VERSION ""

NS_ :

BS_:

BU_: ORIN RPI TOOL DRIVE1 DRIVE2 DRIVE3 DRIVE4 DRIVE5 DRIVE6 FPGA ANY

BO_ 0 ESTOP: 1 ANY
  SG_ MAGIC : 0|8@1+ (1,0) [0|255] "" ORIN,RPI,TOOL,DRIVE1,DRIVE2,DRIVE3,DRIVE4,DRIVE5,DRIVE6,FPGA

BO_ 1 ESTOP_RELEASE: 2 ORIN
  SG_ MASTER_NODE_ID : 0|8@1+ (1,0) [0|31] "" ORIN,RPI,TOOL,DRIVE1,DRIVE2,DRIVE3,DRIVE4,DRIVE5,DRIVE6,FPGA
  SG_ MASTER_TERM : 8|8@1+ (1,0) [0|255] "" ORIN,RPI,TOOL,DRIVE1,DRIVE2,DRIVE3,DRIVE4,DRIVE5,DRIVE6,FPGA

BO_ 2 SYNC: 1 ORIN
  SG_ CYCLE_COUNTER : 0|8@1+ (1,0) [0|255] "" ORIN,RPI,TOOL,DRIVE1,DRIVE2,DRIVE3,DRIVE4,DRIVE5,DRIVE6,FPGA

BO_ 3 NMT: 4 ORIN
  SG_ TARGET_NODE : 0|8@1+ (1,0) [0|31] "" ORIN,RPI,TOOL,DRIVE1,DRIVE2,DRIVE3,DRIVE4,DRIVE5,DRIVE6,FPGA
  SG_ COMMAND : 8|8@1+ (1,0) [0|5] "" ORIN,RPI,TOOL,DRIVE1,DRIVE2,DRIVE3,DRIVE4,DRIVE5,DRIVE6,FPGA
  SG_ MASTER_NODE_ID : 16|8@1+ (1,0) [0|31] "" ORIN,RPI,TOOL,DRIVE1,DRIVE2,DRIVE3,DRIVE4,DRIVE5,DRIVE6,FPGA
  SG_ MASTER_TERM : 24|8@1+ (1,0) [0|255] "" ORIN,RPI,TOOL,DRIVE1,DRIVE2,DRIVE3,DRIVE4,DRIVE5,DRIVE6,FPGA

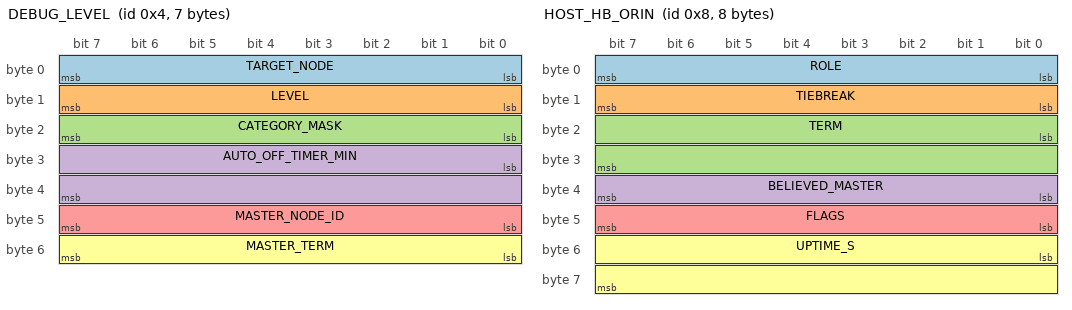
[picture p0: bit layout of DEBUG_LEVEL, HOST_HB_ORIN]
BO_ 4 DEBUG_LEVEL: 7 ORIN
  SG_ TARGET_NODE : 0|8@1+ (1,0) [0|31] "" ORIN,RPI,TOOL,DRIVE1,DRIVE2,DRIVE3,DRIVE4,DRIVE5,DRIVE6,FPGA
  SG_ LEVEL : 8|8@1+ (1,0) [0|3] "" ORIN,RPI,TOOL,DRIVE1,DRIVE2,DRIVE3,DRIVE4,DRIVE5,DRIVE6,FPGA
  SG_ CATEGORY_MASK : 16|8@1+ (1,0) [0|255] "" ORIN,RPI,TOOL,DRIVE1,DRIVE2,DRIVE3,DRIVE4,DRIVE5,DRIVE6,FPGA
  SG_ AUTO_OFF_TIMER_MIN : 24|16@1+ (1,0) [0|65535] "min" ORIN,RPI,TOOL,DRIVE1,DRIVE2,DRIVE3,DRIVE4,DRIVE5,DRIVE6,FPGA
  SG_ MASTER_NODE_ID : 40|8@1+ (1,0) [0|31] "" ORIN,RPI,TOOL,DRIVE1,DRIVE2,DRIVE3,DRIVE4,DRIVE5,DRIVE6,FPGA
  SG_ MASTER_TERM : 48|8@1+ (1,0) [0|255] "" ORIN,RPI,TOOL,DRIVE1,DRIVE2,DRIVE3,DRIVE4,DRIVE5,DRIVE6,FPGA

BO_ 8 HOST_HB_ORIN: 8 ORIN
  SG_ ROLE : 0|8@1+ (1,0) [0|3] "" ORIN,RPI,TOOL
  SG_ TIEBREAK : 8|8@1+ (1,0) [0|255] "" ORIN,RPI,TOOL
  SG_ TERM : 16|16@1+ (1,0) [0|65535] "" ORIN,RPI,TOOL
  SG_ BELIEVED_MASTER : 32|8@1+ (1,0) [0|31] "" ORIN,RPI,TOOL
  SG_ FLAGS : 40|8@1+ (1,0) [0|255] "" ORIN,RPI,TOOL
  SG_ UPTIME_S : 48|16@1+ (1,0) [0|65535] "s" ORIN,RPI,TOOL

BO_ 9 LEAD_REQUEST_ORIN: 2 ORIN
  SG_ REQUESTED_LEADER : 0|8@1+ (1,0) [0|31] "" ORIN,RPI,TOOL
  SG_ REQUEST_COUNTER : 8|8@1+ (1,0) [0|255] "" ORIN,RPI,TOOL

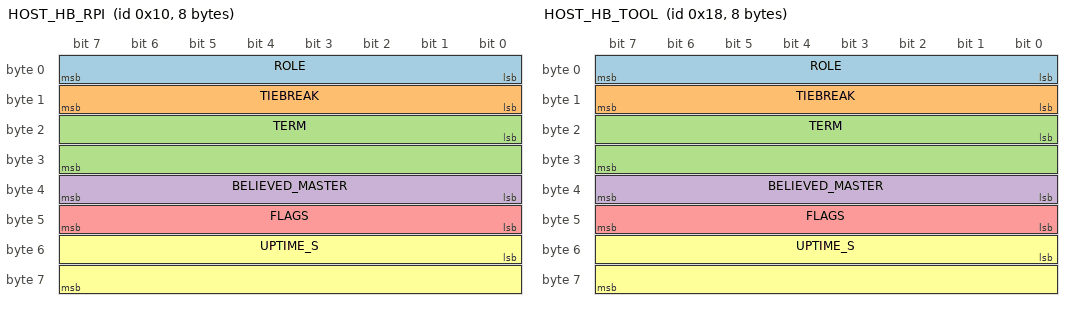
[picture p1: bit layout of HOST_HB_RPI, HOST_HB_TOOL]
BO_ 16 HOST_HB_RPI: 8 RPI
  SG_ ROLE : 0|8@1+ (1,0) [0|3] "" ORIN,RPI,TOOL
  SG_ TIEBREAK : 8|8@1+ (1,0) [0|255] "" ORIN,RPI,TOOL
  SG_ TERM : 16|16@1+ (1,0) [0|65535] "" ORIN,RPI,TOOL
  SG_ BELIEVED_MASTER : 32|8@1+ (1,0) [0|31] "" ORIN,RPI,TOOL
  SG_ FLAGS : 40|8@1+ (1,0) [0|255] "" ORIN,RPI,TOOL
  SG_ UPTIME_S : 48|16@1+ (1,0) [0|65535] "s" ORIN,RPI,TOOL

BO_ 17 LEAD_REQUEST_RPI: 2 RPI
  SG_ REQUESTED_LEADER : 0|8@1+ (1,0) [0|31] "" ORIN,RPI,TOOL
  SG_ REQUEST_COUNTER : 8|8@1+ (1,0) [0|255] "" ORIN,RPI,TOOL

BO_ 24 HOST_HB_TOOL: 8 TOOL
  SG_ ROLE : 0|8@1+ (1,0) [0|3] "" ORIN,RPI,TOOL
  SG_ TIEBREAK : 8|8@1+ (1,0) [0|255] "" ORIN,RPI,TOOL
  SG_ TERM : 16|16@1+ (1,0) [0|65535] "" ORIN,RPI,TOOL
  SG_ BELIEVED_MASTER : 32|8@1+ (1,0) [0|31] "" ORIN,RPI,TOOL
  SG_ FLAGS : 40|8@1+ (1,0) [0|255] "" ORIN,RPI,TOOL
  SG_ UPTIME_S : 48|16@1+ (1,0) [0|65535] "s" ORIN,RPI,TOOL

BO_ 25 LEAD_REQUEST_TOOL: 2 TOOL
  SG_ REQUESTED_LEADER : 0|8@1+ (1,0) [0|31] "" ORIN,RPI,TOOL
  SG_ REQUEST_COUNTER : 8|8@1+ (1,0) [0|255] "" ORIN,RPI,TOOL

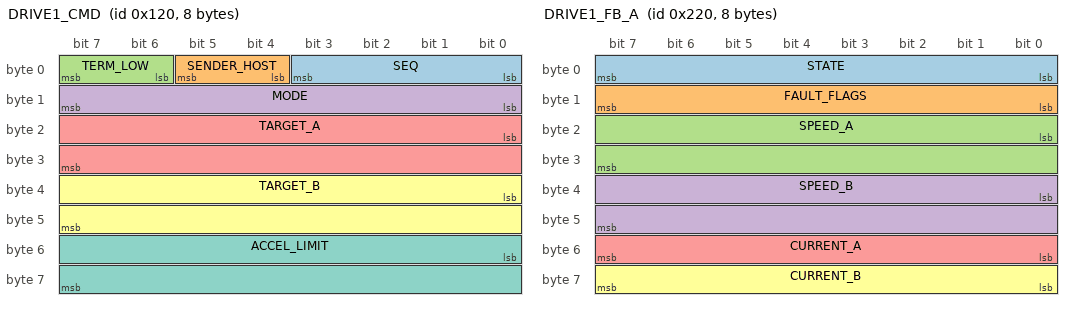
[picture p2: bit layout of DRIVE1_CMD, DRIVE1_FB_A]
BO_ 288 DRIVE1_CMD: 8 ORIN
  SG_ SEQ : 0|4@1+ (1,0) [0|15] "" DRIVE1
  SG_ SENDER_HOST : 4|2@1+ (1,0) [0|3] "" DRIVE1
  SG_ TERM_LOW : 6|2@1+ (1,0) [0|3] "" DRIVE1
  SG_ MODE : 8|8@1+ (1,0) [0|3] "" DRIVE1
  SG_ TARGET_A : 16|16@1- (0.01,0) [-327.68|327.67] "rad/s" DRIVE1
  SG_ TARGET_B : 32|16@1- (0.01,0) [-327.68|327.67] "rad/s" DRIVE1
  SG_ ACCEL_LIMIT : 48|16@1+ (0.01,0) [0|655.35] "rad/s^2" DRIVE1

BO_ 544 DRIVE1_FB_A: 8 DRIVE1
  SG_ STATE : 0|8@1+ (1,0) [0|5] "" ORIN,RPI,TOOL
  SG_ FAULT_FLAGS : 8|8@1+ (1,0) [0|255] "" ORIN,RPI,TOOL
  SG_ SPEED_A : 16|16@1- (0.01,0) [-327.68|327.67] "rad/s" ORIN,RPI,TOOL
  SG_ SPEED_B : 32|16@1- (0.01,0) [-327.68|327.67] "rad/s" ORIN,RPI,TOOL
  SG_ CURRENT_A : 48|8@1+ (0.2,0) [0|51] "A" ORIN,RPI,TOOL
  SG_ CURRENT_B : 56|8@1+ (0.2,0) [0|51] "A" ORIN,RPI,TOOL

BO_ 545 DRIVE1_FB_B: 8 DRIVE1
  SG_ ENCODER_A : 0|32@1- (1,0) [-2147483648|2147483647] "counts" ORIN,RPI,TOOL
  SG_ ENCODER_B : 32|32@1- (1,0) [-2147483648|2147483647] "counts" ORIN,RPI,TOOL

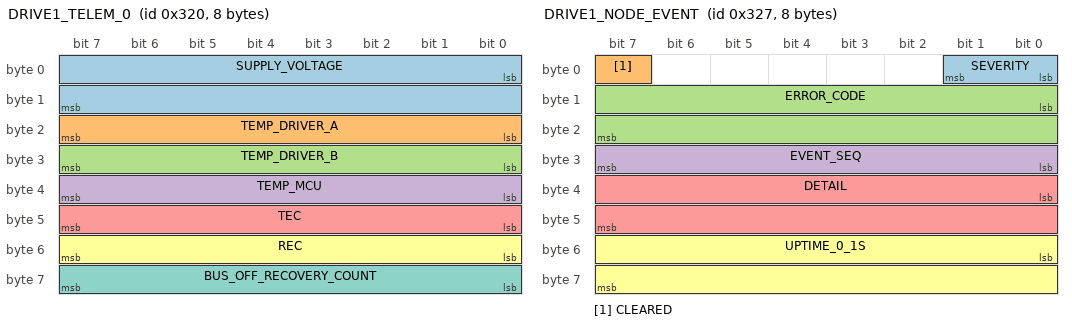
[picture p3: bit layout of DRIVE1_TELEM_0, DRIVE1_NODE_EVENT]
BO_ 800 DRIVE1_TELEM_0: 8 DRIVE1
  SG_ SUPPLY_VOLTAGE : 0|16@1+ (1,0) [0|65535] "mV" ORIN,RPI,TOOL
  SG_ TEMP_DRIVER_A : 16|8@1- (1,0) [-128|127] "degC" ORIN,RPI,TOOL
  SG_ TEMP_DRIVER_B : 24|8@1- (1,0) [-128|127] "degC" ORIN,RPI,TOOL
  SG_ TEMP_MCU : 32|8@1- (1,0) [-128|127] "degC" ORIN,RPI,TOOL
  SG_ TEC : 40|8@1+ (1,0) [0|255] "" ORIN,RPI,TOOL
  SG_ REC : 48|8@1+ (1,0) [0|255] "" ORIN,RPI,TOOL
  SG_ BUS_OFF_RECOVERY_COUNT : 56|8@1+ (1,0) [0|255] "" ORIN,RPI,TOOL

BO_ 801 DRIVE1_TELEM_1: 8 DRIVE1
  SG_ DUTY_A : 0|16@1- (0.01,0) [-327.68|327.67] "%" ORIN,RPI,TOOL
  SG_ DUTY_B : 16|16@1- (0.01,0) [-327.68|327.67] "%" ORIN,RPI,TOOL
  SG_ WATCHDOG_RESET_COUNT : 32|8@1+ (1,0) [0|255] "" ORIN,RPI,TOOL
  SG_ LAST_RESET_CAUSE : 40|8@1+ (1,0) [0|4] "" ORIN,RPI,TOOL
  SG_ COMMANDS_MISSED : 48|16@1+ (1,0) [0|65535] "" ORIN,RPI,TOOL

BO_ 802 DRIVE1_DEBUG_A: 8 DRIVE1
  SG_ SETPOINT : 0|16@1- (0.01,0) [-327.68|327.67] "" ORIN,RPI,TOOL
  SG_ MEASURED : 16|16@1- (0.01,0) [-327.68|327.67] "" ORIN,RPI,TOOL
  SG_ INTEGRATOR : 32|16@1- (0.01,0) [-327.68|327.67] "" ORIN,RPI,TOOL
  SG_ OUTPUT : 48|16@1- (0.01,0) [-327.68|327.67] "" ORIN,RPI,TOOL

BO_ 803 DRIVE1_DEBUG_B: 8 DRIVE1
  SG_ SETPOINT : 0|16@1- (0.01,0) [-327.68|327.67] "" ORIN,RPI,TOOL
  SG_ MEASURED : 16|16@1- (0.01,0) [-327.68|327.67] "" ORIN,RPI,TOOL
  SG_ INTEGRATOR : 32|16@1- (0.01,0) [-327.68|327.67] "" ORIN,RPI,TOOL
  SG_ OUTPUT : 48|16@1- (0.01,0) [-327.68|327.67] "" ORIN,RPI,TOOL

BO_ 807 DRIVE1_NODE_EVENT: 8 DRIVE1
  SG_ SEVERITY : 0|2@1+ (1,0) [0|3] "" ORIN,RPI,TOOL
  SG_ CLEARED : 7|1@1+ (1,0) [0|1] "" ORIN,RPI,TOOL
  SG_ ERROR_CODE : 8|16@1+ (1,0) [0|65535] "" ORIN,RPI,TOOL
  SG_ EVENT_SEQ : 24|8@1+ (1,0) [0|255] "" ORIN,RPI,TOOL
  SG_ DETAIL : 32|16@1+ (1,0) [0|65535] "" ORIN,RPI,TOOL
  SG_ UPTIME_0_1S : 48|16@1+ (0.1,0) [0|6553.5] "s" ORIN,RPI,TOOL

BO_ 1312 DRIVE1_SERVICE_REQ_ORIN: 8 ORIN
  SG_ OPCODE : 0|8@1+ (1,0) [0|7] "" DRIVE1
  SG_ TRANSACTION_ID : 8|8@1+ (1,0) [0|255] "" DRIVE1
  SG_ PARAM_INDEX : 16|16@1+ (1,0) [0|65535] "" DRIVE1
  SG_ VALUE_RAW : 32|32@1+ (1,0) [0|4294967295] "" DRIVE1

BO_ 1313 DRIVE1_SERVICE_REQ_RPI: 8 RPI
  SG_ OPCODE : 0|8@1+ (1,0) [0|7] "" DRIVE1
  SG_ TRANSACTION_ID : 8|8@1+ (1,0) [0|255] "" DRIVE1
  SG_ PARAM_INDEX : 16|16@1+ (1,0) [0|65535] "" DRIVE1
  SG_ VALUE_RAW : 32|32@1+ (1,0) [0|4294967295] "" DRIVE1

BO_ 1314 DRIVE1_SERVICE_REQ_TOOL: 8 TOOL
  SG_ OPCODE : 0|8@1+ (1,0) [0|7] "" DRIVE1
  SG_ TRANSACTION_ID : 8|8@1+ (1,0) [0|255] "" DRIVE1
  SG_ PARAM_INDEX : 16|16@1+ (1,0) [0|65535] "" DRIVE1
  SG_ VALUE_RAW : 32|32@1+ (1,0) [0|4294967295] "" DRIVE1

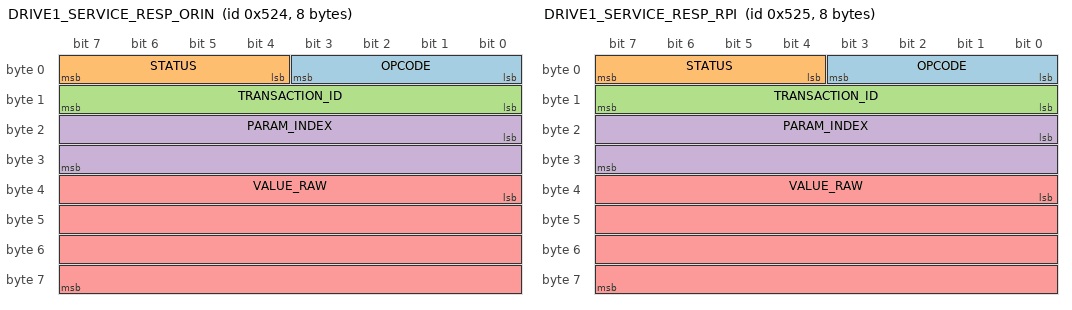
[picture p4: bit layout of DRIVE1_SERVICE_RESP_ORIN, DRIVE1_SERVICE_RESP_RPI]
BO_ 1316 DRIVE1_SERVICE_RESP_ORIN: 8 DRIVE1
  SG_ OPCODE : 0|4@1+ (1,0) [0|7] "" ORIN
  SG_ STATUS : 4|4@1+ (1,0) [0|4] "" ORIN
  SG_ TRANSACTION_ID : 8|8@1+ (1,0) [0|255] "" ORIN
  SG_ PARAM_INDEX : 16|16@1+ (1,0) [0|65535] "" ORIN
  SG_ VALUE_RAW : 32|32@1+ (1,0) [0|4294967295] "" ORIN

BO_ 1317 DRIVE1_SERVICE_RESP_RPI: 8 DRIVE1
  SG_ OPCODE : 0|4@1+ (1,0) [0|7] "" RPI
  SG_ STATUS : 4|4@1+ (1,0) [0|4] "" RPI
  SG_ TRANSACTION_ID : 8|8@1+ (1,0) [0|255] "" RPI
  SG_ PARAM_INDEX : 16|16@1+ (1,0) [0|65535] "" RPI
  SG_ VALUE_RAW : 32|32@1+ (1,0) [0|4294967295] "" RPI

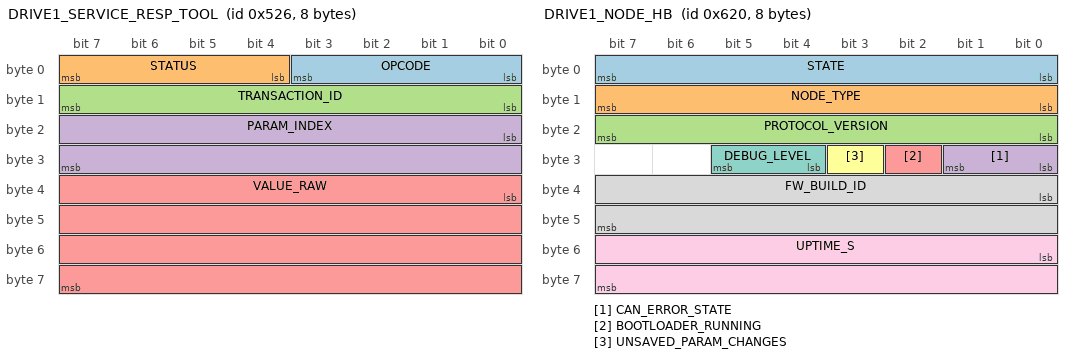
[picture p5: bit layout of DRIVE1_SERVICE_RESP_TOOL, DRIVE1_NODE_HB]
BO_ 1318 DRIVE1_SERVICE_RESP_TOOL: 8 DRIVE1
  SG_ OPCODE : 0|4@1+ (1,0) [0|7] "" TOOL
  SG_ STATUS : 4|4@1+ (1,0) [0|4] "" TOOL
  SG_ TRANSACTION_ID : 8|8@1+ (1,0) [0|255] "" TOOL
  SG_ PARAM_INDEX : 16|16@1+ (1,0) [0|65535] "" TOOL
  SG_ VALUE_RAW : 32|32@1+ (1,0) [0|4294967295] "" TOOL

BO_ 1568 DRIVE1_NODE_HB: 8 DRIVE1
  SG_ STATE : 0|8@1+ (1,0) [0|5] "" ORIN,RPI,TOOL
  SG_ NODE_TYPE : 8|8@1+ (1,0) [0|5] "" ORIN,RPI,TOOL
  SG_ PROTOCOL_VERSION : 16|8@1+ (1,0) [0|255] "" ORIN,RPI,TOOL
  SG_ CAN_ERROR_STATE : 24|2@1+ (1,0) [0|2] "" ORIN,RPI,TOOL
  SG_ BOOTLOADER_RUNNING : 26|1@1+ (1,0) [0|1] "" ORIN,RPI,TOOL
  SG_ UNSAVED_PARAM_CHANGES : 27|1@1+ (1,0) [0|1] "" ORIN,RPI,TOOL
  SG_ DEBUG_LEVEL : 28|2@1+ (1,0) [0|3] "" ORIN,RPI,TOOL
  SG_ FW_BUILD_ID : 32|16@1+ (1,0) [0|65535] "" ORIN,RPI,TOOL
  SG_ UPTIME_S : 48|16@1+ (1,0) [0|65535] "s" ORIN,RPI,TOOL

BO_ 1824 DRIVE1_BOOT_HOST_TO_NODE: 8 ORIN
  SG_ B0 : 0|8@1+ (1,0) [0|255] "" DRIVE1
  SG_ B1 : 8|8@1+ (1,0) [0|255] "" DRIVE1
  SG_ B2 : 16|8@1+ (1,0) [0|255] "" DRIVE1
  SG_ B3 : 24|8@1+ (1,0) [0|255] "" DRIVE1
  SG_ B4 : 32|8@1+ (1,0) [0|255] "" DRIVE1
  SG_ B5 : 40|8@1+ (1,0) [0|255] "" DRIVE1
  SG_ B6 : 48|8@1+ (1,0) [0|255] "" DRIVE1
  SG_ B7 : 56|8@1+ (1,0) [0|255] "" DRIVE1

BO_ 1825 DRIVE1_BOOT_NODE_TO_HOST: 8 DRIVE1
  SG_ B0 : 0|8@1+ (1,0) [0|255] "" ORIN,RPI,TOOL
  SG_ B1 : 8|8@1+ (1,0) [0|255] "" ORIN,RPI,TOOL
  SG_ B2 : 16|8@1+ (1,0) [0|255] "" ORIN,RPI,TOOL
  SG_ B3 : 24|8@1+ (1,0) [0|255] "" ORIN,RPI,TOOL
  SG_ B4 : 32|8@1+ (1,0) [0|255] "" ORIN,RPI,TOOL
  SG_ B5 : 40|8@1+ (1,0) [0|255] "" ORIN,RPI,TOOL
  SG_ B6 : 48|8@1+ (1,0) [0|255] "" ORIN,RPI,TOOL
  SG_ B7 : 56|8@1+ (1,0) [0|255] "" ORIN,RPI,TOOL

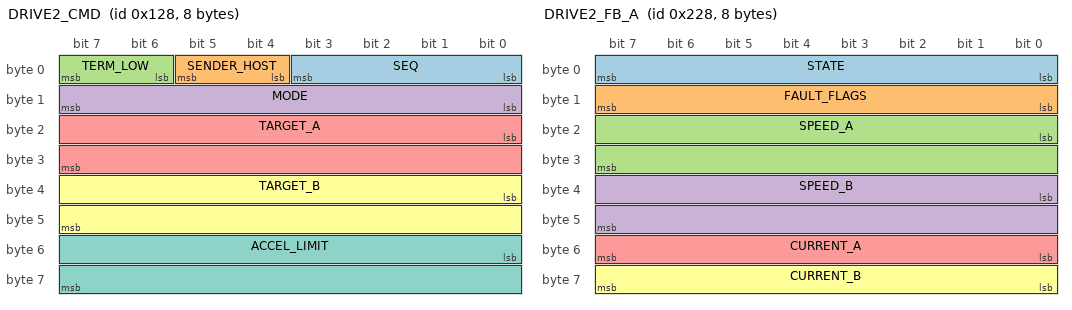
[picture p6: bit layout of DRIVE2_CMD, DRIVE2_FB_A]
BO_ 296 DRIVE2_CMD: 8 ORIN
  SG_ SEQ : 0|4@1+ (1,0) [0|15] "" DRIVE2
  SG_ SENDER_HOST : 4|2@1+ (1,0) [0|3] "" DRIVE2
  SG_ TERM_LOW : 6|2@1+ (1,0) [0|3] "" DRIVE2
  SG_ MODE : 8|8@1+ (1,0) [0|3] "" DRIVE2
  SG_ TARGET_A : 16|16@1- (0.01,0) [-327.68|327.67] "rad/s" DRIVE2
  SG_ TARGET_B : 32|16@1- (0.01,0) [-327.68|327.67] "rad/s" DRIVE2
  SG_ ACCEL_LIMIT : 48|16@1+ (0.01,0) [0|655.35] "rad/s^2" DRIVE2

BO_ 552 DRIVE2_FB_A: 8 DRIVE2
  SG_ STATE : 0|8@1+ (1,0) [0|5] "" ORIN,RPI,TOOL
  SG_ FAULT_FLAGS : 8|8@1+ (1,0) [0|255] "" ORIN,RPI,TOOL
  SG_ SPEED_A : 16|16@1- (0.01,0) [-327.68|327.67] "rad/s" ORIN,RPI,TOOL
  SG_ SPEED_B : 32|16@1- (0.01,0) [-327.68|327.67] "rad/s" ORIN,RPI,TOOL
  SG_ CURRENT_A : 48|8@1+ (0.2,0) [0|51] "A" ORIN,RPI,TOOL
  SG_ CURRENT_B : 56|8@1+ (0.2,0) [0|51] "A" ORIN,RPI,TOOL

BO_ 553 DRIVE2_FB_B: 8 DRIVE2
  SG_ ENCODER_A : 0|32@1- (1,0) [-2147483648|2147483647] "counts" ORIN,RPI,TOOL
  SG_ ENCODER_B : 32|32@1- (1,0) [-2147483648|2147483647] "counts" ORIN,RPI,TOOL

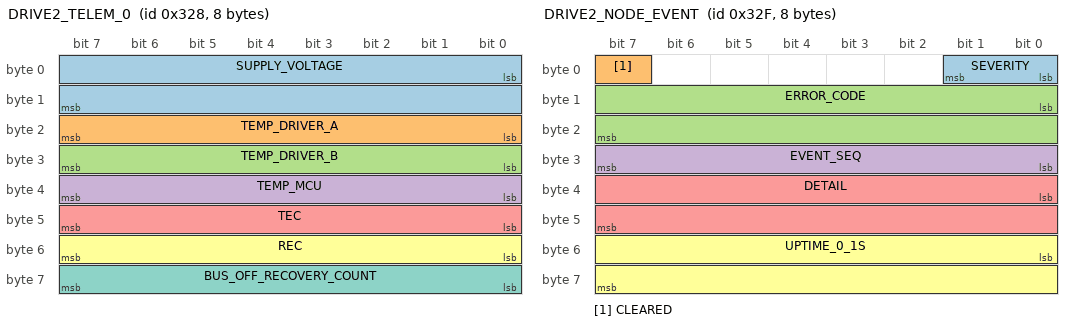
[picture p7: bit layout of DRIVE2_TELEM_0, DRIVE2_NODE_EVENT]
BO_ 808 DRIVE2_TELEM_0: 8 DRIVE2
  SG_ SUPPLY_VOLTAGE : 0|16@1+ (1,0) [0|65535] "mV" ORIN,RPI,TOOL
  SG_ TEMP_DRIVER_A : 16|8@1- (1,0) [-128|127] "degC" ORIN,RPI,TOOL
  SG_ TEMP_DRIVER_B : 24|8@1- (1,0) [-128|127] "degC" ORIN,RPI,TOOL
  SG_ TEMP_MCU : 32|8@1- (1,0) [-128|127] "degC" ORIN,RPI,TOOL
  SG_ TEC : 40|8@1+ (1,0) [0|255] "" ORIN,RPI,TOOL
  SG_ REC : 48|8@1+ (1,0) [0|255] "" ORIN,RPI,TOOL
  SG_ BUS_OFF_RECOVERY_COUNT : 56|8@1+ (1,0) [0|255] "" ORIN,RPI,TOOL

BO_ 809 DRIVE2_TELEM_1: 8 DRIVE2
  SG_ DUTY_A : 0|16@1- (0.01,0) [-327.68|327.67] "%" ORIN,RPI,TOOL
  SG_ DUTY_B : 16|16@1- (0.01,0) [-327.68|327.67] "%" ORIN,RPI,TOOL
  SG_ WATCHDOG_RESET_COUNT : 32|8@1+ (1,0) [0|255] "" ORIN,RPI,TOOL
  SG_ LAST_RESET_CAUSE : 40|8@1+ (1,0) [0|4] "" ORIN,RPI,TOOL
  SG_ COMMANDS_MISSED : 48|16@1+ (1,0) [0|65535] "" ORIN,RPI,TOOL

BO_ 810 DRIVE2_DEBUG_A: 8 DRIVE2
  SG_ SETPOINT : 0|16@1- (0.01,0) [-327.68|327.67] "" ORIN,RPI,TOOL
  SG_ MEASURED : 16|16@1- (0.01,0) [-327.68|327.67] "" ORIN,RPI,TOOL
  SG_ INTEGRATOR : 32|16@1- (0.01,0) [-327.68|327.67] "" ORIN,RPI,TOOL
  SG_ OUTPUT : 48|16@1- (0.01,0) [-327.68|327.67] "" ORIN,RPI,TOOL

BO_ 811 DRIVE2_DEBUG_B: 8 DRIVE2
  SG_ SETPOINT : 0|16@1- (0.01,0) [-327.68|327.67] "" ORIN,RPI,TOOL
  SG_ MEASURED : 16|16@1- (0.01,0) [-327.68|327.67] "" ORIN,RPI,TOOL
  SG_ INTEGRATOR : 32|16@1- (0.01,0) [-327.68|327.67] "" ORIN,RPI,TOOL
  SG_ OUTPUT : 48|16@1- (0.01,0) [-327.68|327.67] "" ORIN,RPI,TOOL

BO_ 815 DRIVE2_NODE_EVENT: 8 DRIVE2
  SG_ SEVERITY : 0|2@1+ (1,0) [0|3] "" ORIN,RPI,TOOL
  SG_ CLEARED : 7|1@1+ (1,0) [0|1] "" ORIN,RPI,TOOL
  SG_ ERROR_CODE : 8|16@1+ (1,0) [0|65535] "" ORIN,RPI,TOOL
  SG_ EVENT_SEQ : 24|8@1+ (1,0) [0|255] "" ORIN,RPI,TOOL
  SG_ DETAIL : 32|16@1+ (1,0) [0|65535] "" ORIN,RPI,TOOL
  SG_ UPTIME_0_1S : 48|16@1+ (0.1,0) [0|6553.5] "s" ORIN,RPI,TOOL

BO_ 1320 DRIVE2_SERVICE_REQ_ORIN: 8 ORIN
  SG_ OPCODE : 0|8@1+ (1,0) [0|7] "" DRIVE2
  SG_ TRANSACTION_ID : 8|8@1+ (1,0) [0|255] "" DRIVE2
  SG_ PARAM_INDEX : 16|16@1+ (1,0) [0|65535] "" DRIVE2
  SG_ VALUE_RAW : 32|32@1+ (1,0) [0|4294967295] "" DRIVE2

BO_ 1321 DRIVE2_SERVICE_REQ_RPI: 8 RPI
  SG_ OPCODE : 0|8@1+ (1,0) [0|7] "" DRIVE2
  SG_ TRANSACTION_ID : 8|8@1+ (1,0) [0|255] "" DRIVE2
  SG_ PARAM_INDEX : 16|16@1+ (1,0) [0|65535] "" DRIVE2
  SG_ VALUE_RAW : 32|32@1+ (1,0) [0|4294967295] "" DRIVE2

BO_ 1322 DRIVE2_SERVICE_REQ_TOOL: 8 TOOL
  SG_ OPCODE : 0|8@1+ (1,0) [0|7] "" DRIVE2
  SG_ TRANSACTION_ID : 8|8@1+ (1,0) [0|255] "" DRIVE2
  SG_ PARAM_INDEX : 16|16@1+ (1,0) [0|65535] "" DRIVE2
  SG_ VALUE_RAW : 32|32@1+ (1,0) [0|4294967295] "" DRIVE2

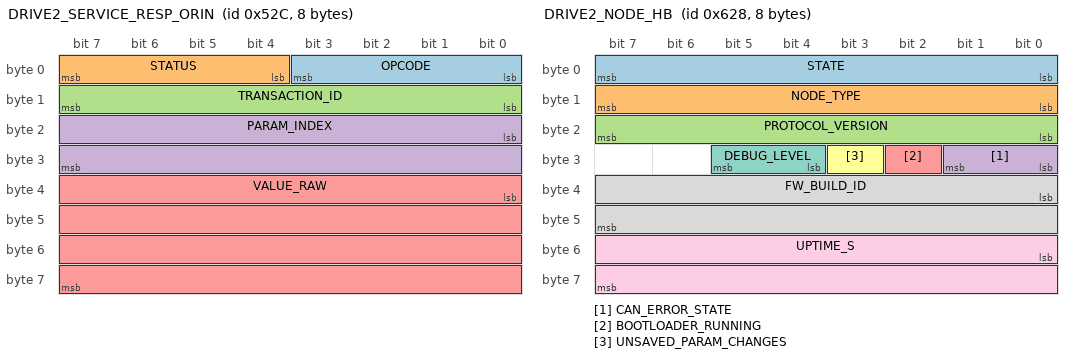
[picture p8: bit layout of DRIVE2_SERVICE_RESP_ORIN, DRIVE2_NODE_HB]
BO_ 1324 DRIVE2_SERVICE_RESP_ORIN: 8 DRIVE2
  SG_ OPCODE : 0|4@1+ (1,0) [0|7] "" ORIN
  SG_ STATUS : 4|4@1+ (1,0) [0|4] "" ORIN
  SG_ TRANSACTION_ID : 8|8@1+ (1,0) [0|255] "" ORIN
  SG_ PARAM_INDEX : 16|16@1+ (1,0) [0|65535] "" ORIN
  SG_ VALUE_RAW : 32|32@1+ (1,0) [0|4294967295] "" ORIN

BO_ 1325 DRIVE2_SERVICE_RESP_RPI: 8 DRIVE2
  SG_ OPCODE : 0|4@1+ (1,0) [0|7] "" RPI
  SG_ STATUS : 4|4@1+ (1,0) [0|4] "" RPI
  SG_ TRANSACTION_ID : 8|8@1+ (1,0) [0|255] "" RPI
  SG_ PARAM_INDEX : 16|16@1+ (1,0) [0|65535] "" RPI
  SG_ VALUE_RAW : 32|32@1+ (1,0) [0|4294967295] "" RPI

BO_ 1326 DRIVE2_SERVICE_RESP_TOOL: 8 DRIVE2
  SG_ OPCODE : 0|4@1+ (1,0) [0|7] "" TOOL
  SG_ STATUS : 4|4@1+ (1,0) [0|4] "" TOOL
  SG_ TRANSACTION_ID : 8|8@1+ (1,0) [0|255] "" TOOL
  SG_ PARAM_INDEX : 16|16@1+ (1,0) [0|65535] "" TOOL
  SG_ VALUE_RAW : 32|32@1+ (1,0) [0|4294967295] "" TOOL

BO_ 1576 DRIVE2_NODE_HB: 8 DRIVE2
  SG_ STATE : 0|8@1+ (1,0) [0|5] "" ORIN,RPI,TOOL
  SG_ NODE_TYPE : 8|8@1+ (1,0) [0|5] "" ORIN,RPI,TOOL
  SG_ PROTOCOL_VERSION : 16|8@1+ (1,0) [0|255] "" ORIN,RPI,TOOL
  SG_ CAN_ERROR_STATE : 24|2@1+ (1,0) [0|2] "" ORIN,RPI,TOOL
  SG_ BOOTLOADER_RUNNING : 26|1@1+ (1,0) [0|1] "" ORIN,RPI,TOOL
  SG_ UNSAVED_PARAM_CHANGES : 27|1@1+ (1,0) [0|1] "" ORIN,RPI,TOOL
  SG_ DEBUG_LEVEL : 28|2@1+ (1,0) [0|3] "" ORIN,RPI,TOOL
  SG_ FW_BUILD_ID : 32|16@1+ (1,0) [0|65535] "" ORIN,RPI,TOOL
  SG_ UPTIME_S : 48|16@1+ (1,0) [0|65535] "s" ORIN,RPI,TOOL

BO_ 1832 DRIVE2_BOOT_HOST_TO_NODE: 8 ORIN
  SG_ B0 : 0|8@1+ (1,0) [0|255] "" DRIVE2
  SG_ B1 : 8|8@1+ (1,0) [0|255] "" DRIVE2
  SG_ B2 : 16|8@1+ (1,0) [0|255] "" DRIVE2
  SG_ B3 : 24|8@1+ (1,0) [0|255] "" DRIVE2
  SG_ B4 : 32|8@1+ (1,0) [0|255] "" DRIVE2
  SG_ B5 : 40|8@1+ (1,0) [0|255] "" DRIVE2
  SG_ B6 : 48|8@1+ (1,0) [0|255] "" DRIVE2
  SG_ B7 : 56|8@1+ (1,0) [0|255] "" DRIVE2

BO_ 1833 DRIVE2_BOOT_NODE_TO_HOST: 8 DRIVE2
  SG_ B0 : 0|8@1+ (1,0) [0|255] "" ORIN,RPI,TOOL
  SG_ B1 : 8|8@1+ (1,0) [0|255] "" ORIN,RPI,TOOL
  SG_ B2 : 16|8@1+ (1,0) [0|255] "" ORIN,RPI,TOOL
  SG_ B3 : 24|8@1+ (1,0) [0|255] "" ORIN,RPI,TOOL
  SG_ B4 : 32|8@1+ (1,0) [0|255] "" ORIN,RPI,TOOL
  SG_ B5 : 40|8@1+ (1,0) [0|255] "" ORIN,RPI,TOOL
  SG_ B6 : 48|8@1+ (1,0) [0|255] "" ORIN,RPI,TOOL
  SG_ B7 : 56|8@1+ (1,0) [0|255] "" ORIN,RPI,TOOL

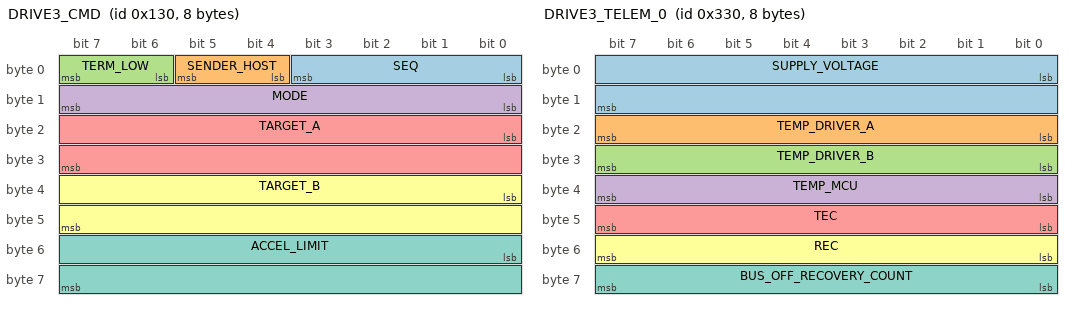
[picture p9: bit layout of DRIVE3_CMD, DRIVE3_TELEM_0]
BO_ 304 DRIVE3_CMD: 8 ORIN
  SG_ SEQ : 0|4@1+ (1,0) [0|15] "" DRIVE3
  SG_ SENDER_HOST : 4|2@1+ (1,0) [0|3] "" DRIVE3
  SG_ TERM_LOW : 6|2@1+ (1,0) [0|3] "" DRIVE3
  SG_ MODE : 8|8@1+ (1,0) [0|3] "" DRIVE3
  SG_ TARGET_A : 16|16@1- (0.01,0) [-327.68|327.67] "rad/s" DRIVE3
  SG_ TARGET_B : 32|16@1- (0.01,0) [-327.68|327.67] "rad/s" DRIVE3
  SG_ ACCEL_LIMIT : 48|16@1+ (0.01,0) [0|655.35] "rad/s^2" DRIVE3

BO_ 560 DRIVE3_FB_A: 8 DRIVE3
  SG_ STATE : 0|8@1+ (1,0) [0|5] "" ORIN,RPI,TOOL
  SG_ FAULT_FLAGS : 8|8@1+ (1,0) [0|255] "" ORIN,RPI,TOOL
  SG_ SPEED_A : 16|16@1- (0.01,0) [-327.68|327.67] "rad/s" ORIN,RPI,TOOL
  SG_ SPEED_B : 32|16@1- (0.01,0) [-327.68|327.67] "rad/s" ORIN,RPI,TOOL
  SG_ CURRENT_A : 48|8@1+ (0.2,0) [0|51] "A" ORIN,RPI,TOOL
  SG_ CURRENT_B : 56|8@1+ (0.2,0) [0|51] "A" ORIN,RPI,TOOL

BO_ 561 DRIVE3_FB_B: 8 DRIVE3
  SG_ ENCODER_A : 0|32@1- (1,0) [-2147483648|2147483647] "counts" ORIN,RPI,TOOL
  SG_ ENCODER_B : 32|32@1- (1,0) [-2147483648|2147483647] "counts" ORIN,RPI,TOOL

BO_ 816 DRIVE3_TELEM_0: 8 DRIVE3
  SG_ SUPPLY_VOLTAGE : 0|16@1+ (1,0) [0|65535] "mV" ORIN,RPI,TOOL
  SG_ TEMP_DRIVER_A : 16|8@1- (1,0) [-128|127] "degC" ORIN,RPI,TOOL
  SG_ TEMP_DRIVER_B : 24|8@1- (1,0) [-128|127] "degC" ORIN,RPI,TOOL
  SG_ TEMP_MCU : 32|8@1- (1,0) [-128|127] "degC" ORIN,RPI,TOOL
  SG_ TEC : 40|8@1+ (1,0) [0|255] "" ORIN,RPI,TOOL
  SG_ REC : 48|8@1+ (1,0) [0|255] "" ORIN,RPI,TOOL
  SG_ BUS_OFF_RECOVERY_COUNT : 56|8@1+ (1,0) [0|255] "" ORIN,RPI,TOOL

BO_ 817 DRIVE3_TELEM_1: 8 DRIVE3
  SG_ DUTY_A : 0|16@1- (0.01,0) [-327.68|327.67] "%" ORIN,RPI,TOOL
  SG_ DUTY_B : 16|16@1- (0.01,0) [-327.68|327.67] "%" ORIN,RPI,TOOL
  SG_ WATCHDOG_RESET_COUNT : 32|8@1+ (1,0) [0|255] "" ORIN,RPI,TOOL
  SG_ LAST_RESET_CAUSE : 40|8@1+ (1,0) [0|4] "" ORIN,RPI,TOOL
  SG_ COMMANDS_MISSED : 48|16@1+ (1,0) [0|65535] "" ORIN,RPI,TOOL

BO_ 818 DRIVE3_DEBUG_A: 8 DRIVE3
  SG_ SETPOINT : 0|16@1- (0.01,0) [-327.68|327.67] "" ORIN,RPI,TOOL
  SG_ MEASURED : 16|16@1- (0.01,0) [-327.68|327.67] "" ORIN,RPI,TOOL
  SG_ INTEGRATOR : 32|16@1- (0.01,0) [-327.68|327.67] "" ORIN,RPI,TOOL
  SG_ OUTPUT : 48|16@1- (0.01,0) [-327.68|327.67] "" ORIN,RPI,TOOL

BO_ 819 DRIVE3_DEBUG_B: 8 DRIVE3
  SG_ SETPOINT : 0|16@1- (0.01,0) [-327.68|327.67] "" ORIN,RPI,TOOL
  SG_ MEASURED : 16|16@1- (0.01,0) [-327.68|327.67] "" ORIN,RPI,TOOL
  SG_ INTEGRATOR : 32|16@1- (0.01,0) [-327.68|327.67] "" ORIN,RPI,TOOL
  SG_ OUTPUT : 48|16@1- (0.01,0) [-327.68|327.67] "" ORIN,RPI,TOOL

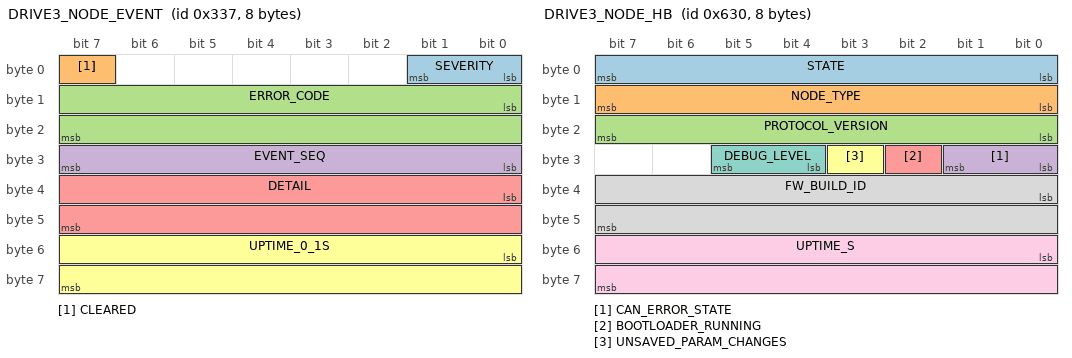
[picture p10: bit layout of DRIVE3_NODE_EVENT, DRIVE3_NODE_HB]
BO_ 823 DRIVE3_NODE_EVENT: 8 DRIVE3
  SG_ SEVERITY : 0|2@1+ (1,0) [0|3] "" ORIN,RPI,TOOL
  SG_ CLEARED : 7|1@1+ (1,0) [0|1] "" ORIN,RPI,TOOL
  SG_ ERROR_CODE : 8|16@1+ (1,0) [0|65535] "" ORIN,RPI,TOOL
  SG_ EVENT_SEQ : 24|8@1+ (1,0) [0|255] "" ORIN,RPI,TOOL
  SG_ DETAIL : 32|16@1+ (1,0) [0|65535] "" ORIN,RPI,TOOL
  SG_ UPTIME_0_1S : 48|16@1+ (0.1,0) [0|6553.5] "s" ORIN,RPI,TOOL

BO_ 1328 DRIVE3_SERVICE_REQ_ORIN: 8 ORIN
  SG_ OPCODE : 0|8@1+ (1,0) [0|7] "" DRIVE3
  SG_ TRANSACTION_ID : 8|8@1+ (1,0) [0|255] "" DRIVE3
  SG_ PARAM_INDEX : 16|16@1+ (1,0) [0|65535] "" DRIVE3
  SG_ VALUE_RAW : 32|32@1+ (1,0) [0|4294967295] "" DRIVE3

BO_ 1329 DRIVE3_SERVICE_REQ_RPI: 8 RPI
  SG_ OPCODE : 0|8@1+ (1,0) [0|7] "" DRIVE3
  SG_ TRANSACTION_ID : 8|8@1+ (1,0) [0|255] "" DRIVE3
  SG_ PARAM_INDEX : 16|16@1+ (1,0) [0|65535] "" DRIVE3
  SG_ VALUE_RAW : 32|32@1+ (1,0) [0|4294967295] "" DRIVE3

BO_ 1330 DRIVE3_SERVICE_REQ_TOOL: 8 TOOL
  SG_ OPCODE : 0|8@1+ (1,0) [0|7] "" DRIVE3
  SG_ TRANSACTION_ID : 8|8@1+ (1,0) [0|255] "" DRIVE3
  SG_ PARAM_INDEX : 16|16@1+ (1,0) [0|65535] "" DRIVE3
  SG_ VALUE_RAW : 32|32@1+ (1,0) [0|4294967295] "" DRIVE3

BO_ 1332 DRIVE3_SERVICE_RESP_ORIN: 8 DRIVE3
  SG_ OPCODE : 0|4@1+ (1,0) [0|7] "" ORIN
  SG_ STATUS : 4|4@1+ (1,0) [0|4] "" ORIN
  SG_ TRANSACTION_ID : 8|8@1+ (1,0) [0|255] "" ORIN
  SG_ PARAM_INDEX : 16|16@1+ (1,0) [0|65535] "" ORIN
  SG_ VALUE_RAW : 32|32@1+ (1,0) [0|4294967295] "" ORIN

BO_ 1333 DRIVE3_SERVICE_RESP_RPI: 8 DRIVE3
  SG_ OPCODE : 0|4@1+ (1,0) [0|7] "" RPI
  SG_ STATUS : 4|4@1+ (1,0) [0|4] "" RPI
  SG_ TRANSACTION_ID : 8|8@1+ (1,0) [0|255] "" RPI
  SG_ PARAM_INDEX : 16|16@1+ (1,0) [0|65535] "" RPI
  SG_ VALUE_RAW : 32|32@1+ (1,0) [0|4294967295] "" RPI

BO_ 1334 DRIVE3_SERVICE_RESP_TOOL: 8 DRIVE3
  SG_ OPCODE : 0|4@1+ (1,0) [0|7] "" TOOL
  SG_ STATUS : 4|4@1+ (1,0) [0|4] "" TOOL
  SG_ TRANSACTION_ID : 8|8@1+ (1,0) [0|255] "" TOOL
  SG_ PARAM_INDEX : 16|16@1+ (1,0) [0|65535] "" TOOL
  SG_ VALUE_RAW : 32|32@1+ (1,0) [0|4294967295] "" TOOL

BO_ 1584 DRIVE3_NODE_HB: 8 DRIVE3
  SG_ STATE : 0|8@1+ (1,0) [0|5] "" ORIN,RPI,TOOL
  SG_ NODE_TYPE : 8|8@1+ (1,0) [0|5] "" ORIN,RPI,TOOL
  SG_ PROTOCOL_VERSION : 16|8@1+ (1,0) [0|255] "" ORIN,RPI,TOOL
  SG_ CAN_ERROR_STATE : 24|2@1+ (1,0) [0|2] "" ORIN,RPI,TOOL
  SG_ BOOTLOADER_RUNNING : 26|1@1+ (1,0) [0|1] "" ORIN,RPI,TOOL
  SG_ UNSAVED_PARAM_CHANGES : 27|1@1+ (1,0) [0|1] "" ORIN,RPI,TOOL
  SG_ DEBUG_LEVEL : 28|2@1+ (1,0) [0|3] "" ORIN,RPI,TOOL
  SG_ FW_BUILD_ID : 32|16@1+ (1,0) [0|65535] "" ORIN,RPI,TOOL
  SG_ UPTIME_S : 48|16@1+ (1,0) [0|65535] "s" ORIN,RPI,TOOL

BO_ 1840 DRIVE3_BOOT_HOST_TO_NODE: 8 ORIN
  SG_ B0 : 0|8@1+ (1,0) [0|255] "" DRIVE3
  SG_ B1 : 8|8@1+ (1,0) [0|255] "" DRIVE3
  SG_ B2 : 16|8@1+ (1,0) [0|255] "" DRIVE3
  SG_ B3 : 24|8@1+ (1,0) [0|255] "" DRIVE3
  SG_ B4 : 32|8@1+ (1,0) [0|255] "" DRIVE3
  SG_ B5 : 40|8@1+ (1,0) [0|255] "" DRIVE3
  SG_ B6 : 48|8@1+ (1,0) [0|255] "" DRIVE3
  SG_ B7 : 56|8@1+ (1,0) [0|255] "" DRIVE3

BO_ 1841 DRIVE3_BOOT_NODE_TO_HOST: 8 DRIVE3
  SG_ B0 : 0|8@1+ (1,0) [0|255] "" ORIN,RPI,TOOL
  SG_ B1 : 8|8@1+ (1,0) [0|255] "" ORIN,RPI,TOOL
  SG_ B2 : 16|8@1+ (1,0) [0|255] "" ORIN,RPI,TOOL
  SG_ B3 : 24|8@1+ (1,0) [0|255] "" ORIN,RPI,TOOL
  SG_ B4 : 32|8@1+ (1,0) [0|255] "" ORIN,RPI,TOOL
  SG_ B5 : 40|8@1+ (1,0) [0|255] "" ORIN,RPI,TOOL
  SG_ B6 : 48|8@1+ (1,0) [0|255] "" ORIN,RPI,TOOL
  SG_ B7 : 56|8@1+ (1,0) [0|255] "" ORIN,RPI,TOOL

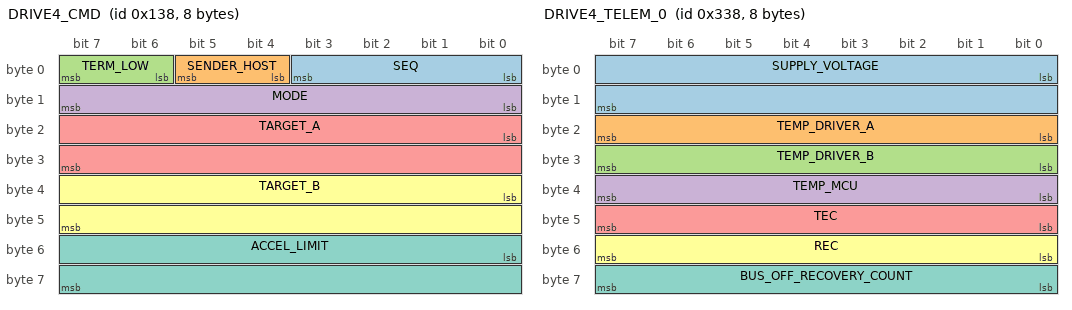
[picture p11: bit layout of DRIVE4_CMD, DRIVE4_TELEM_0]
BO_ 312 DRIVE4_CMD: 8 ORIN
  SG_ SEQ : 0|4@1+ (1,0) [0|15] "" DRIVE4
  SG_ SENDER_HOST : 4|2@1+ (1,0) [0|3] "" DRIVE4
  SG_ TERM_LOW : 6|2@1+ (1,0) [0|3] "" DRIVE4
  SG_ MODE : 8|8@1+ (1,0) [0|3] "" DRIVE4
  SG_ TARGET_A : 16|16@1- (0.01,0) [-327.68|327.67] "rad/s" DRIVE4
  SG_ TARGET_B : 32|16@1- (0.01,0) [-327.68|327.67] "rad/s" DRIVE4
  SG_ ACCEL_LIMIT : 48|16@1+ (0.01,0) [0|655.35] "rad/s^2" DRIVE4

BO_ 568 DRIVE4_FB_A: 8 DRIVE4
  SG_ STATE : 0|8@1+ (1,0) [0|5] "" ORIN,RPI,TOOL
  SG_ FAULT_FLAGS : 8|8@1+ (1,0) [0|255] "" ORIN,RPI,TOOL
  SG_ SPEED_A : 16|16@1- (0.01,0) [-327.68|327.67] "rad/s" ORIN,RPI,TOOL
  SG_ SPEED_B : 32|16@1- (0.01,0) [-327.68|327.67] "rad/s" ORIN,RPI,TOOL
  SG_ CURRENT_A : 48|8@1+ (0.2,0) [0|51] "A" ORIN,RPI,TOOL
  SG_ CURRENT_B : 56|8@1+ (0.2,0) [0|51] "A" ORIN,RPI,TOOL

BO_ 569 DRIVE4_FB_B: 8 DRIVE4
  SG_ ENCODER_A : 0|32@1- (1,0) [-2147483648|2147483647] "counts" ORIN,RPI,TOOL
  SG_ ENCODER_B : 32|32@1- (1,0) [-2147483648|2147483647] "counts" ORIN,RPI,TOOL

BO_ 824 DRIVE4_TELEM_0: 8 DRIVE4
  SG_ SUPPLY_VOLTAGE : 0|16@1+ (1,0) [0|65535] "mV" ORIN,RPI,TOOL
  SG_ TEMP_DRIVER_A : 16|8@1- (1,0) [-128|127] "degC" ORIN,RPI,TOOL
  SG_ TEMP_DRIVER_B : 24|8@1- (1,0) [-128|127] "degC" ORIN,RPI,TOOL
  SG_ TEMP_MCU : 32|8@1- (1,0) [-128|127] "degC" ORIN,RPI,TOOL
  SG_ TEC : 40|8@1+ (1,0) [0|255] "" ORIN,RPI,TOOL
  SG_ REC : 48|8@1+ (1,0) [0|255] "" ORIN,RPI,TOOL
  SG_ BUS_OFF_RECOVERY_COUNT : 56|8@1+ (1,0) [0|255] "" ORIN,RPI,TOOL

BO_ 825 DRIVE4_TELEM_1: 8 DRIVE4
  SG_ DUTY_A : 0|16@1- (0.01,0) [-327.68|327.67] "%" ORIN,RPI,TOOL
  SG_ DUTY_B : 16|16@1- (0.01,0) [-327.68|327.67] "%" ORIN,RPI,TOOL
  SG_ WATCHDOG_RESET_COUNT : 32|8@1+ (1,0) [0|255] "" ORIN,RPI,TOOL
  SG_ LAST_RESET_CAUSE : 40|8@1+ (1,0) [0|4] "" ORIN,RPI,TOOL
  SG_ COMMANDS_MISSED : 48|16@1+ (1,0) [0|65535] "" ORIN,RPI,TOOL

BO_ 826 DRIVE4_DEBUG_A: 8 DRIVE4
  SG_ SETPOINT : 0|16@1- (0.01,0) [-327.68|327.67] "" ORIN,RPI,TOOL
  SG_ MEASURED : 16|16@1- (0.01,0) [-327.68|327.67] "" ORIN,RPI,TOOL
  SG_ INTEGRATOR : 32|16@1- (0.01,0) [-327.68|327.67] "" ORIN,RPI,TOOL
  SG_ OUTPUT : 48|16@1- (0.01,0) [-327.68|327.67] "" ORIN,RPI,TOOL

BO_ 827 DRIVE4_DEBUG_B: 8 DRIVE4
  SG_ SETPOINT : 0|16@1- (0.01,0) [-327.68|327.67] "" ORIN,RPI,TOOL
  SG_ MEASURED : 16|16@1- (0.01,0) [-327.68|327.67] "" ORIN,RPI,TOOL
  SG_ INTEGRATOR : 32|16@1- (0.01,0) [-327.68|327.67] "" ORIN,RPI,TOOL
  SG_ OUTPUT : 48|16@1- (0.01,0) [-327.68|327.67] "" ORIN,RPI,TOOL

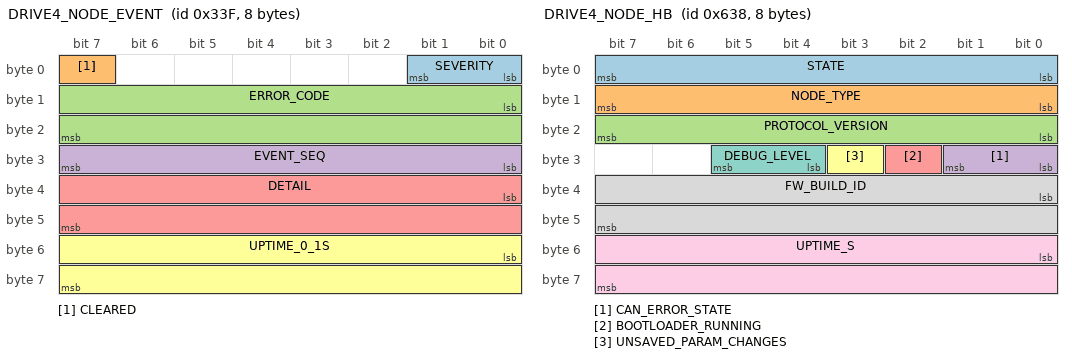
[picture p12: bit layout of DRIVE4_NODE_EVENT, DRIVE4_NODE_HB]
BO_ 831 DRIVE4_NODE_EVENT: 8 DRIVE4
  SG_ SEVERITY : 0|2@1+ (1,0) [0|3] "" ORIN,RPI,TOOL
  SG_ CLEARED : 7|1@1+ (1,0) [0|1] "" ORIN,RPI,TOOL
  SG_ ERROR_CODE : 8|16@1+ (1,0) [0|65535] "" ORIN,RPI,TOOL
  SG_ EVENT_SEQ : 24|8@1+ (1,0) [0|255] "" ORIN,RPI,TOOL
  SG_ DETAIL : 32|16@1+ (1,0) [0|65535] "" ORIN,RPI,TOOL
  SG_ UPTIME_0_1S : 48|16@1+ (0.1,0) [0|6553.5] "s" ORIN,RPI,TOOL

BO_ 1336 DRIVE4_SERVICE_REQ_ORIN: 8 ORIN
  SG_ OPCODE : 0|8@1+ (1,0) [0|7] "" DRIVE4
  SG_ TRANSACTION_ID : 8|8@1+ (1,0) [0|255] "" DRIVE4
  SG_ PARAM_INDEX : 16|16@1+ (1,0) [0|65535] "" DRIVE4
  SG_ VALUE_RAW : 32|32@1+ (1,0) [0|4294967295] "" DRIVE4

BO_ 1337 DRIVE4_SERVICE_REQ_RPI: 8 RPI
  SG_ OPCODE : 0|8@1+ (1,0) [0|7] "" DRIVE4
  SG_ TRANSACTION_ID : 8|8@1+ (1,0) [0|255] "" DRIVE4
  SG_ PARAM_INDEX : 16|16@1+ (1,0) [0|65535] "" DRIVE4
  SG_ VALUE_RAW : 32|32@1+ (1,0) [0|4294967295] "" DRIVE4

BO_ 1338 DRIVE4_SERVICE_REQ_TOOL: 8 TOOL
  SG_ OPCODE : 0|8@1+ (1,0) [0|7] "" DRIVE4
  SG_ TRANSACTION_ID : 8|8@1+ (1,0) [0|255] "" DRIVE4
  SG_ PARAM_INDEX : 16|16@1+ (1,0) [0|65535] "" DRIVE4
  SG_ VALUE_RAW : 32|32@1+ (1,0) [0|4294967295] "" DRIVE4

BO_ 1340 DRIVE4_SERVICE_RESP_ORIN: 8 DRIVE4
  SG_ OPCODE : 0|4@1+ (1,0) [0|7] "" ORIN
  SG_ STATUS : 4|4@1+ (1,0) [0|4] "" ORIN
  SG_ TRANSACTION_ID : 8|8@1+ (1,0) [0|255] "" ORIN
  SG_ PARAM_INDEX : 16|16@1+ (1,0) [0|65535] "" ORIN
  SG_ VALUE_RAW : 32|32@1+ (1,0) [0|4294967295] "" ORIN

BO_ 1341 DRIVE4_SERVICE_RESP_RPI: 8 DRIVE4
  SG_ OPCODE : 0|4@1+ (1,0) [0|7] "" RPI
  SG_ STATUS : 4|4@1+ (1,0) [0|4] "" RPI
  SG_ TRANSACTION_ID : 8|8@1+ (1,0) [0|255] "" RPI
  SG_ PARAM_INDEX : 16|16@1+ (1,0) [0|65535] "" RPI
  SG_ VALUE_RAW : 32|32@1+ (1,0) [0|4294967295] "" RPI

BO_ 1342 DRIVE4_SERVICE_RESP_TOOL: 8 DRIVE4
  SG_ OPCODE : 0|4@1+ (1,0) [0|7] "" TOOL
  SG_ STATUS : 4|4@1+ (1,0) [0|4] "" TOOL
  SG_ TRANSACTION_ID : 8|8@1+ (1,0) [0|255] "" TOOL
  SG_ PARAM_INDEX : 16|16@1+ (1,0) [0|65535] "" TOOL
  SG_ VALUE_RAW : 32|32@1+ (1,0) [0|4294967295] "" TOOL

BO_ 1592 DRIVE4_NODE_HB: 8 DRIVE4
  SG_ STATE : 0|8@1+ (1,0) [0|5] "" ORIN,RPI,TOOL
  SG_ NODE_TYPE : 8|8@1+ (1,0) [0|5] "" ORIN,RPI,TOOL
  SG_ PROTOCOL_VERSION : 16|8@1+ (1,0) [0|255] "" ORIN,RPI,TOOL
  SG_ CAN_ERROR_STATE : 24|2@1+ (1,0) [0|2] "" ORIN,RPI,TOOL
  SG_ BOOTLOADER_RUNNING : 26|1@1+ (1,0) [0|1] "" ORIN,RPI,TOOL
  SG_ UNSAVED_PARAM_CHANGES : 27|1@1+ (1,0) [0|1] "" ORIN,RPI,TOOL
  SG_ DEBUG_LEVEL : 28|2@1+ (1,0) [0|3] "" ORIN,RPI,TOOL
  SG_ FW_BUILD_ID : 32|16@1+ (1,0) [0|65535] "" ORIN,RPI,TOOL
  SG_ UPTIME_S : 48|16@1+ (1,0) [0|65535] "s" ORIN,RPI,TOOL

BO_ 1848 DRIVE4_BOOT_HOST_TO_NODE: 8 ORIN
  SG_ B0 : 0|8@1+ (1,0) [0|255] "" DRIVE4
  SG_ B1 : 8|8@1+ (1,0) [0|255] "" DRIVE4
  SG_ B2 : 16|8@1+ (1,0) [0|255] "" DRIVE4
  SG_ B3 : 24|8@1+ (1,0) [0|255] "" DRIVE4
  SG_ B4 : 32|8@1+ (1,0) [0|255] "" DRIVE4
  SG_ B5 : 40|8@1+ (1,0) [0|255] "" DRIVE4
  SG_ B6 : 48|8@1+ (1,0) [0|255] "" DRIVE4
  SG_ B7 : 56|8@1+ (1,0) [0|255] "" DRIVE4

BO_ 1849 DRIVE4_BOOT_NODE_TO_HOST: 8 DRIVE4
  SG_ B0 : 0|8@1+ (1,0) [0|255] "" ORIN,RPI,TOOL
  SG_ B1 : 8|8@1+ (1,0) [0|255] "" ORIN,RPI,TOOL
  SG_ B2 : 16|8@1+ (1,0) [0|255] "" ORIN,RPI,TOOL
  SG_ B3 : 24|8@1+ (1,0) [0|255] "" ORIN,RPI,TOOL
  SG_ B4 : 32|8@1+ (1,0) [0|255] "" ORIN,RPI,TOOL
  SG_ B5 : 40|8@1+ (1,0) [0|255] "" ORIN,RPI,TOOL
  SG_ B6 : 48|8@1+ (1,0) [0|255] "" ORIN,RPI,TOOL
  SG_ B7 : 56|8@1+ (1,0) [0|255] "" ORIN,RPI,TOOL

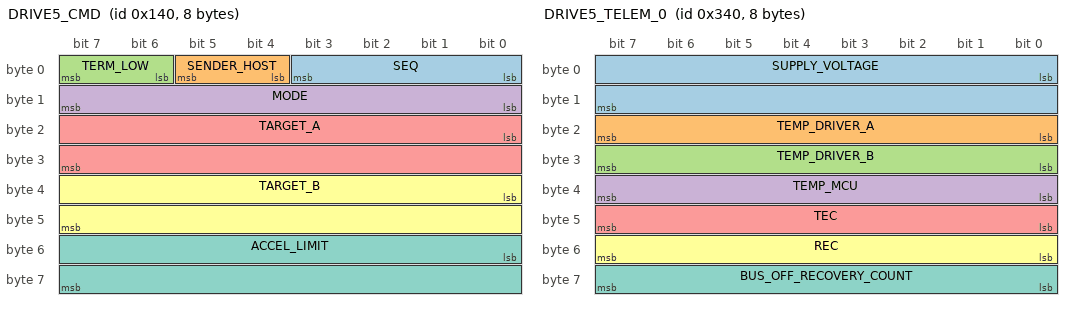
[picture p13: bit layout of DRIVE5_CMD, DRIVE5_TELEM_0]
BO_ 320 DRIVE5_CMD: 8 ORIN
  SG_ SEQ : 0|4@1+ (1,0) [0|15] "" DRIVE5
  SG_ SENDER_HOST : 4|2@1+ (1,0) [0|3] "" DRIVE5
  SG_ TERM_LOW : 6|2@1+ (1,0) [0|3] "" DRIVE5
  SG_ MODE : 8|8@1+ (1,0) [0|3] "" DRIVE5
  SG_ TARGET_A : 16|16@1- (0.01,0) [-327.68|327.67] "rad/s" DRIVE5
  SG_ TARGET_B : 32|16@1- (0.01,0) [-327.68|327.67] "rad/s" DRIVE5
  SG_ ACCEL_LIMIT : 48|16@1+ (0.01,0) [0|655.35] "rad/s^2" DRIVE5

BO_ 576 DRIVE5_FB_A: 8 DRIVE5
  SG_ STATE : 0|8@1+ (1,0) [0|5] "" ORIN,RPI,TOOL
  SG_ FAULT_FLAGS : 8|8@1+ (1,0) [0|255] "" ORIN,RPI,TOOL
  SG_ SPEED_A : 16|16@1- (0.01,0) [-327.68|327.67] "rad/s" ORIN,RPI,TOOL
  SG_ SPEED_B : 32|16@1- (0.01,0) [-327.68|327.67] "rad/s" ORIN,RPI,TOOL
  SG_ CURRENT_A : 48|8@1+ (0.2,0) [0|51] "A" ORIN,RPI,TOOL
  SG_ CURRENT_B : 56|8@1+ (0.2,0) [0|51] "A" ORIN,RPI,TOOL

BO_ 577 DRIVE5_FB_B: 8 DRIVE5
  SG_ ENCODER_A : 0|32@1- (1,0) [-2147483648|2147483647] "counts" ORIN,RPI,TOOL
  SG_ ENCODER_B : 32|32@1- (1,0) [-2147483648|2147483647] "counts" ORIN,RPI,TOOL

BO_ 832 DRIVE5_TELEM_0: 8 DRIVE5
  SG_ SUPPLY_VOLTAGE : 0|16@1+ (1,0) [0|65535] "mV" ORIN,RPI,TOOL
  SG_ TEMP_DRIVER_A : 16|8@1- (1,0) [-128|127] "degC" ORIN,RPI,TOOL
  SG_ TEMP_DRIVER_B : 24|8@1- (1,0) [-128|127] "degC" ORIN,RPI,TOOL
  SG_ TEMP_MCU : 32|8@1- (1,0) [-128|127] "degC" ORIN,RPI,TOOL
  SG_ TEC : 40|8@1+ (1,0) [0|255] "" ORIN,RPI,TOOL
  SG_ REC : 48|8@1+ (1,0) [0|255] "" ORIN,RPI,TOOL
  SG_ BUS_OFF_RECOVERY_COUNT : 56|8@1+ (1,0) [0|255] "" ORIN,RPI,TOOL

BO_ 833 DRIVE5_TELEM_1: 8 DRIVE5
  SG_ DUTY_A : 0|16@1- (0.01,0) [-327.68|327.67] "%" ORIN,RPI,TOOL
  SG_ DUTY_B : 16|16@1- (0.01,0) [-327.68|327.67] "%" ORIN,RPI,TOOL
  SG_ WATCHDOG_RESET_COUNT : 32|8@1+ (1,0) [0|255] "" ORIN,RPI,TOOL
  SG_ LAST_RESET_CAUSE : 40|8@1+ (1,0) [0|4] "" ORIN,RPI,TOOL
  SG_ COMMANDS_MISSED : 48|16@1+ (1,0) [0|65535] "" ORIN,RPI,TOOL

BO_ 834 DRIVE5_DEBUG_A: 8 DRIVE5
  SG_ SETPOINT : 0|16@1- (0.01,0) [-327.68|327.67] "" ORIN,RPI,TOOL
  SG_ MEASURED : 16|16@1- (0.01,0) [-327.68|327.67] "" ORIN,RPI,TOOL
  SG_ INTEGRATOR : 32|16@1- (0.01,0) [-327.68|327.67] "" ORIN,RPI,TOOL
  SG_ OUTPUT : 48|16@1- (0.01,0) [-327.68|327.67] "" ORIN,RPI,TOOL

BO_ 835 DRIVE5_DEBUG_B: 8 DRIVE5
  SG_ SETPOINT : 0|16@1- (0.01,0) [-327.68|327.67] "" ORIN,RPI,TOOL
  SG_ MEASURED : 16|16@1- (0.01,0) [-327.68|327.67] "" ORIN,RPI,TOOL
  SG_ INTEGRATOR : 32|16@1- (0.01,0) [-327.68|327.67] "" ORIN,RPI,TOOL
  SG_ OUTPUT : 48|16@1- (0.01,0) [-327.68|327.67] "" ORIN,RPI,TOOL

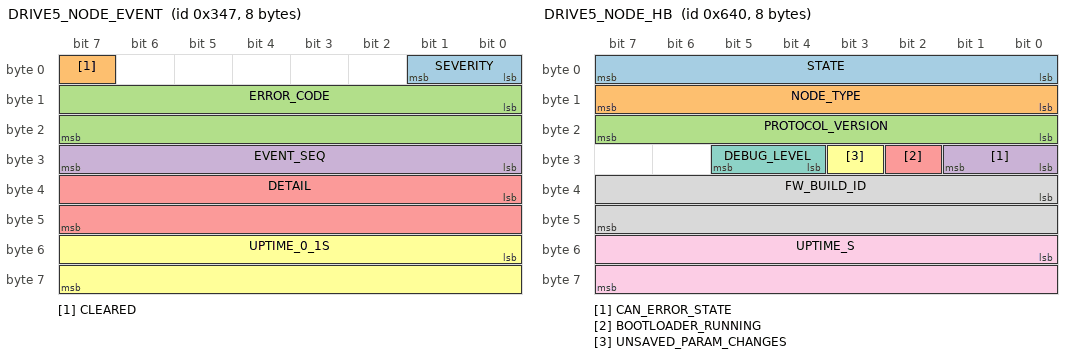
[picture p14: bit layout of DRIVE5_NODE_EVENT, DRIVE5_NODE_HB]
BO_ 839 DRIVE5_NODE_EVENT: 8 DRIVE5
  SG_ SEVERITY : 0|2@1+ (1,0) [0|3] "" ORIN,RPI,TOOL
  SG_ CLEARED : 7|1@1+ (1,0) [0|1] "" ORIN,RPI,TOOL
  SG_ ERROR_CODE : 8|16@1+ (1,0) [0|65535] "" ORIN,RPI,TOOL
  SG_ EVENT_SEQ : 24|8@1+ (1,0) [0|255] "" ORIN,RPI,TOOL
  SG_ DETAIL : 32|16@1+ (1,0) [0|65535] "" ORIN,RPI,TOOL
  SG_ UPTIME_0_1S : 48|16@1+ (0.1,0) [0|6553.5] "s" ORIN,RPI,TOOL

BO_ 1344 DRIVE5_SERVICE_REQ_ORIN: 8 ORIN
  SG_ OPCODE : 0|8@1+ (1,0) [0|7] "" DRIVE5
  SG_ TRANSACTION_ID : 8|8@1+ (1,0) [0|255] "" DRIVE5
  SG_ PARAM_INDEX : 16|16@1+ (1,0) [0|65535] "" DRIVE5
  SG_ VALUE_RAW : 32|32@1+ (1,0) [0|4294967295] "" DRIVE5

BO_ 1345 DRIVE5_SERVICE_REQ_RPI: 8 RPI
  SG_ OPCODE : 0|8@1+ (1,0) [0|7] "" DRIVE5
  SG_ TRANSACTION_ID : 8|8@1+ (1,0) [0|255] "" DRIVE5
  SG_ PARAM_INDEX : 16|16@1+ (1,0) [0|65535] "" DRIVE5
  SG_ VALUE_RAW : 32|32@1+ (1,0) [0|4294967295] "" DRIVE5

BO_ 1346 DRIVE5_SERVICE_REQ_TOOL: 8 TOOL
  SG_ OPCODE : 0|8@1+ (1,0) [0|7] "" DRIVE5
  SG_ TRANSACTION_ID : 8|8@1+ (1,0) [0|255] "" DRIVE5
  SG_ PARAM_INDEX : 16|16@1+ (1,0) [0|65535] "" DRIVE5
  SG_ VALUE_RAW : 32|32@1+ (1,0) [0|4294967295] "" DRIVE5

BO_ 1348 DRIVE5_SERVICE_RESP_ORIN: 8 DRIVE5
  SG_ OPCODE : 0|4@1+ (1,0) [0|7] "" ORIN
  SG_ STATUS : 4|4@1+ (1,0) [0|4] "" ORIN
  SG_ TRANSACTION_ID : 8|8@1+ (1,0) [0|255] "" ORIN
  SG_ PARAM_INDEX : 16|16@1+ (1,0) [0|65535] "" ORIN
  SG_ VALUE_RAW : 32|32@1+ (1,0) [0|4294967295] "" ORIN

BO_ 1349 DRIVE5_SERVICE_RESP_RPI: 8 DRIVE5
  SG_ OPCODE : 0|4@1+ (1,0) [0|7] "" RPI
  SG_ STATUS : 4|4@1+ (1,0) [0|4] "" RPI
  SG_ TRANSACTION_ID : 8|8@1+ (1,0) [0|255] "" RPI
  SG_ PARAM_INDEX : 16|16@1+ (1,0) [0|65535] "" RPI
  SG_ VALUE_RAW : 32|32@1+ (1,0) [0|4294967295] "" RPI

BO_ 1350 DRIVE5_SERVICE_RESP_TOOL: 8 DRIVE5
  SG_ OPCODE : 0|4@1+ (1,0) [0|7] "" TOOL
  SG_ STATUS : 4|4@1+ (1,0) [0|4] "" TOOL
  SG_ TRANSACTION_ID : 8|8@1+ (1,0) [0|255] "" TOOL
  SG_ PARAM_INDEX : 16|16@1+ (1,0) [0|65535] "" TOOL
  SG_ VALUE_RAW : 32|32@1+ (1,0) [0|4294967295] "" TOOL

BO_ 1600 DRIVE5_NODE_HB: 8 DRIVE5
  SG_ STATE : 0|8@1+ (1,0) [0|5] "" ORIN,RPI,TOOL
  SG_ NODE_TYPE : 8|8@1+ (1,0) [0|5] "" ORIN,RPI,TOOL
  SG_ PROTOCOL_VERSION : 16|8@1+ (1,0) [0|255] "" ORIN,RPI,TOOL
  SG_ CAN_ERROR_STATE : 24|2@1+ (1,0) [0|2] "" ORIN,RPI,TOOL
  SG_ BOOTLOADER_RUNNING : 26|1@1+ (1,0) [0|1] "" ORIN,RPI,TOOL
  SG_ UNSAVED_PARAM_CHANGES : 27|1@1+ (1,0) [0|1] "" ORIN,RPI,TOOL
  SG_ DEBUG_LEVEL : 28|2@1+ (1,0) [0|3] "" ORIN,RPI,TOOL
  SG_ FW_BUILD_ID : 32|16@1+ (1,0) [0|65535] "" ORIN,RPI,TOOL
  SG_ UPTIME_S : 48|16@1+ (1,0) [0|65535] "s" ORIN,RPI,TOOL

BO_ 1856 DRIVE5_BOOT_HOST_TO_NODE: 8 ORIN
  SG_ B0 : 0|8@1+ (1,0) [0|255] "" DRIVE5
  SG_ B1 : 8|8@1+ (1,0) [0|255] "" DRIVE5
  SG_ B2 : 16|8@1+ (1,0) [0|255] "" DRIVE5
  SG_ B3 : 24|8@1+ (1,0) [0|255] "" DRIVE5
  SG_ B4 : 32|8@1+ (1,0) [0|255] "" DRIVE5
  SG_ B5 : 40|8@1+ (1,0) [0|255] "" DRIVE5
  SG_ B6 : 48|8@1+ (1,0) [0|255] "" DRIVE5
  SG_ B7 : 56|8@1+ (1,0) [0|255] "" DRIVE5

BO_ 1857 DRIVE5_BOOT_NODE_TO_HOST: 8 DRIVE5
  SG_ B0 : 0|8@1+ (1,0) [0|255] "" ORIN,RPI,TOOL
  SG_ B1 : 8|8@1+ (1,0) [0|255] "" ORIN,RPI,TOOL
  SG_ B2 : 16|8@1+ (1,0) [0|255] "" ORIN,RPI,TOOL
  SG_ B3 : 24|8@1+ (1,0) [0|255] "" ORIN,RPI,TOOL
  SG_ B4 : 32|8@1+ (1,0) [0|255] "" ORIN,RPI,TOOL
  SG_ B5 : 40|8@1+ (1,0) [0|255] "" ORIN,RPI,TOOL
  SG_ B6 : 48|8@1+ (1,0) [0|255] "" ORIN,RPI,TOOL
  SG_ B7 : 56|8@1+ (1,0) [0|255] "" ORIN,RPI,TOOL

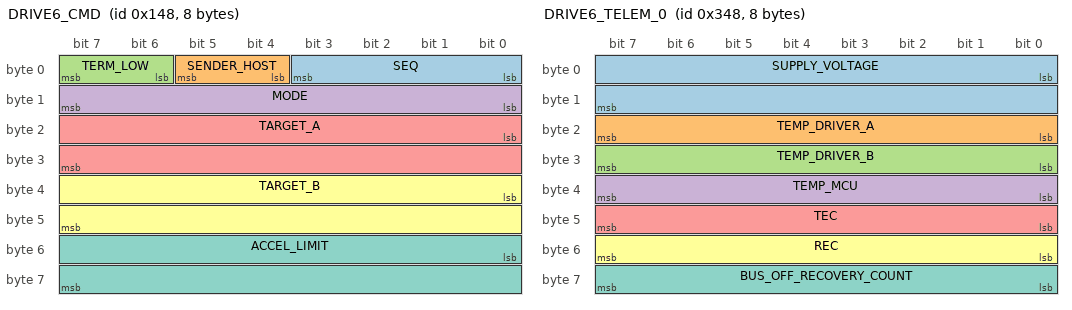
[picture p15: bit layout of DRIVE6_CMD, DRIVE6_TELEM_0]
BO_ 328 DRIVE6_CMD: 8 ORIN
  SG_ SEQ : 0|4@1+ (1,0) [0|15] "" DRIVE6
  SG_ SENDER_HOST : 4|2@1+ (1,0) [0|3] "" DRIVE6
  SG_ TERM_LOW : 6|2@1+ (1,0) [0|3] "" DRIVE6
  SG_ MODE : 8|8@1+ (1,0) [0|3] "" DRIVE6
  SG_ TARGET_A : 16|16@1- (0.01,0) [-327.68|327.67] "rad/s" DRIVE6
  SG_ TARGET_B : 32|16@1- (0.01,0) [-327.68|327.67] "rad/s" DRIVE6
  SG_ ACCEL_LIMIT : 48|16@1+ (0.01,0) [0|655.35] "rad/s^2" DRIVE6

BO_ 584 DRIVE6_FB_A: 8 DRIVE6
  SG_ STATE : 0|8@1+ (1,0) [0|5] "" ORIN,RPI,TOOL
  SG_ FAULT_FLAGS : 8|8@1+ (1,0) [0|255] "" ORIN,RPI,TOOL
  SG_ SPEED_A : 16|16@1- (0.01,0) [-327.68|327.67] "rad/s" ORIN,RPI,TOOL
  SG_ SPEED_B : 32|16@1- (0.01,0) [-327.68|327.67] "rad/s" ORIN,RPI,TOOL
  SG_ CURRENT_A : 48|8@1+ (0.2,0) [0|51] "A" ORIN,RPI,TOOL
  SG_ CURRENT_B : 56|8@1+ (0.2,0) [0|51] "A" ORIN,RPI,TOOL

BO_ 585 DRIVE6_FB_B: 8 DRIVE6
  SG_ ENCODER_A : 0|32@1- (1,0) [-2147483648|2147483647] "counts" ORIN,RPI,TOOL
  SG_ ENCODER_B : 32|32@1- (1,0) [-2147483648|2147483647] "counts" ORIN,RPI,TOOL

BO_ 840 DRIVE6_TELEM_0: 8 DRIVE6
  SG_ SUPPLY_VOLTAGE : 0|16@1+ (1,0) [0|65535] "mV" ORIN,RPI,TOOL
  SG_ TEMP_DRIVER_A : 16|8@1- (1,0) [-128|127] "degC" ORIN,RPI,TOOL
  SG_ TEMP_DRIVER_B : 24|8@1- (1,0) [-128|127] "degC" ORIN,RPI,TOOL
  SG_ TEMP_MCU : 32|8@1- (1,0) [-128|127] "degC" ORIN,RPI,TOOL
  SG_ TEC : 40|8@1+ (1,0) [0|255] "" ORIN,RPI,TOOL
  SG_ REC : 48|8@1+ (1,0) [0|255] "" ORIN,RPI,TOOL
  SG_ BUS_OFF_RECOVERY_COUNT : 56|8@1+ (1,0) [0|255] "" ORIN,RPI,TOOL

BO_ 841 DRIVE6_TELEM_1: 8 DRIVE6
  SG_ DUTY_A : 0|16@1- (0.01,0) [-327.68|327.67] "%" ORIN,RPI,TOOL
  SG_ DUTY_B : 16|16@1- (0.01,0) [-327.68|327.67] "%" ORIN,RPI,TOOL
  SG_ WATCHDOG_RESET_COUNT : 32|8@1+ (1,0) [0|255] "" ORIN,RPI,TOOL
  SG_ LAST_RESET_CAUSE : 40|8@1+ (1,0) [0|4] "" ORIN,RPI,TOOL
  SG_ COMMANDS_MISSED : 48|16@1+ (1,0) [0|65535] "" ORIN,RPI,TOOL

BO_ 842 DRIVE6_DEBUG_A: 8 DRIVE6
  SG_ SETPOINT : 0|16@1- (0.01,0) [-327.68|327.67] "" ORIN,RPI,TOOL
  SG_ MEASURED : 16|16@1- (0.01,0) [-327.68|327.67] "" ORIN,RPI,TOOL
  SG_ INTEGRATOR : 32|16@1- (0.01,0) [-327.68|327.67] "" ORIN,RPI,TOOL
  SG_ OUTPUT : 48|16@1- (0.01,0) [-327.68|327.67] "" ORIN,RPI,TOOL

BO_ 843 DRIVE6_DEBUG_B: 8 DRIVE6
  SG_ SETPOINT : 0|16@1- (0.01,0) [-327.68|327.67] "" ORIN,RPI,TOOL
  SG_ MEASURED : 16|16@1- (0.01,0) [-327.68|327.67] "" ORIN,RPI,TOOL
  SG_ INTEGRATOR : 32|16@1- (0.01,0) [-327.68|327.67] "" ORIN,RPI,TOOL
  SG_ OUTPUT : 48|16@1- (0.01,0) [-327.68|327.67] "" ORIN,RPI,TOOL

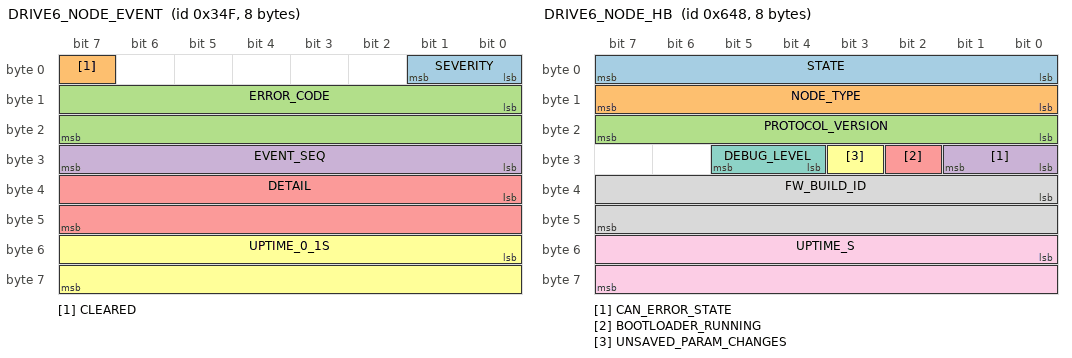
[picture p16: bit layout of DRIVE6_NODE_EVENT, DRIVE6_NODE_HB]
BO_ 847 DRIVE6_NODE_EVENT: 8 DRIVE6
  SG_ SEVERITY : 0|2@1+ (1,0) [0|3] "" ORIN,RPI,TOOL
  SG_ CLEARED : 7|1@1+ (1,0) [0|1] "" ORIN,RPI,TOOL
  SG_ ERROR_CODE : 8|16@1+ (1,0) [0|65535] "" ORIN,RPI,TOOL
  SG_ EVENT_SEQ : 24|8@1+ (1,0) [0|255] "" ORIN,RPI,TOOL
  SG_ DETAIL : 32|16@1+ (1,0) [0|65535] "" ORIN,RPI,TOOL
  SG_ UPTIME_0_1S : 48|16@1+ (0.1,0) [0|6553.5] "s" ORIN,RPI,TOOL

BO_ 1352 DRIVE6_SERVICE_REQ_ORIN: 8 ORIN
  SG_ OPCODE : 0|8@1+ (1,0) [0|7] "" DRIVE6
  SG_ TRANSACTION_ID : 8|8@1+ (1,0) [0|255] "" DRIVE6
  SG_ PARAM_INDEX : 16|16@1+ (1,0) [0|65535] "" DRIVE6
  SG_ VALUE_RAW : 32|32@1+ (1,0) [0|4294967295] "" DRIVE6

BO_ 1353 DRIVE6_SERVICE_REQ_RPI: 8 RPI
  SG_ OPCODE : 0|8@1+ (1,0) [0|7] "" DRIVE6
  SG_ TRANSACTION_ID : 8|8@1+ (1,0) [0|255] "" DRIVE6
  SG_ PARAM_INDEX : 16|16@1+ (1,0) [0|65535] "" DRIVE6
  SG_ VALUE_RAW : 32|32@1+ (1,0) [0|4294967295] "" DRIVE6

BO_ 1354 DRIVE6_SERVICE_REQ_TOOL: 8 TOOL
  SG_ OPCODE : 0|8@1+ (1,0) [0|7] "" DRIVE6
  SG_ TRANSACTION_ID : 8|8@1+ (1,0) [0|255] "" DRIVE6
  SG_ PARAM_INDEX : 16|16@1+ (1,0) [0|65535] "" DRIVE6
  SG_ VALUE_RAW : 32|32@1+ (1,0) [0|4294967295] "" DRIVE6

BO_ 1356 DRIVE6_SERVICE_RESP_ORIN: 8 DRIVE6
  SG_ OPCODE : 0|4@1+ (1,0) [0|7] "" ORIN
  SG_ STATUS : 4|4@1+ (1,0) [0|4] "" ORIN
  SG_ TRANSACTION_ID : 8|8@1+ (1,0) [0|255] "" ORIN
  SG_ PARAM_INDEX : 16|16@1+ (1,0) [0|65535] "" ORIN
  SG_ VALUE_RAW : 32|32@1+ (1,0) [0|4294967295] "" ORIN

BO_ 1357 DRIVE6_SERVICE_RESP_RPI: 8 DRIVE6
  SG_ OPCODE : 0|4@1+ (1,0) [0|7] "" RPI
  SG_ STATUS : 4|4@1+ (1,0) [0|4] "" RPI
  SG_ TRANSACTION_ID : 8|8@1+ (1,0) [0|255] "" RPI
  SG_ PARAM_INDEX : 16|16@1+ (1,0) [0|65535] "" RPI
  SG_ VALUE_RAW : 32|32@1+ (1,0) [0|4294967295] "" RPI

BO_ 1358 DRIVE6_SERVICE_RESP_TOOL: 8 DRIVE6
  SG_ OPCODE : 0|4@1+ (1,0) [0|7] "" TOOL
  SG_ STATUS : 4|4@1+ (1,0) [0|4] "" TOOL
  SG_ TRANSACTION_ID : 8|8@1+ (1,0) [0|255] "" TOOL
  SG_ PARAM_INDEX : 16|16@1+ (1,0) [0|65535] "" TOOL
  SG_ VALUE_RAW : 32|32@1+ (1,0) [0|4294967295] "" TOOL

BO_ 1608 DRIVE6_NODE_HB: 8 DRIVE6
  SG_ STATE : 0|8@1+ (1,0) [0|5] "" ORIN,RPI,TOOL
  SG_ NODE_TYPE : 8|8@1+ (1,0) [0|5] "" ORIN,RPI,TOOL
  SG_ PROTOCOL_VERSION : 16|8@1+ (1,0) [0|255] "" ORIN,RPI,TOOL
  SG_ CAN_ERROR_STATE : 24|2@1+ (1,0) [0|2] "" ORIN,RPI,TOOL
  SG_ BOOTLOADER_RUNNING : 26|1@1+ (1,0) [0|1] "" ORIN,RPI,TOOL
  SG_ UNSAVED_PARAM_CHANGES : 27|1@1+ (1,0) [0|1] "" ORIN,RPI,TOOL
  SG_ DEBUG_LEVEL : 28|2@1+ (1,0) [0|3] "" ORIN,RPI,TOOL
  SG_ FW_BUILD_ID : 32|16@1+ (1,0) [0|65535] "" ORIN,RPI,TOOL
  SG_ UPTIME_S : 48|16@1+ (1,0) [0|65535] "s" ORIN,RPI,TOOL

BO_ 1864 DRIVE6_BOOT_HOST_TO_NODE: 8 ORIN
  SG_ B0 : 0|8@1+ (1,0) [0|255] "" DRIVE6
  SG_ B1 : 8|8@1+ (1,0) [0|255] "" DRIVE6
  SG_ B2 : 16|8@1+ (1,0) [0|255] "" DRIVE6
  SG_ B3 : 24|8@1+ (1,0) [0|255] "" DRIVE6
  SG_ B4 : 32|8@1+ (1,0) [0|255] "" DRIVE6
  SG_ B5 : 40|8@1+ (1,0) [0|255] "" DRIVE6
  SG_ B6 : 48|8@1+ (1,0) [0|255] "" DRIVE6
  SG_ B7 : 56|8@1+ (1,0) [0|255] "" DRIVE6

BO_ 1865 DRIVE6_BOOT_NODE_TO_HOST: 8 DRIVE6
  SG_ B0 : 0|8@1+ (1,0) [0|255] "" ORIN,RPI,TOOL
  SG_ B1 : 8|8@1+ (1,0) [0|255] "" ORIN,RPI,TOOL
  SG_ B2 : 16|8@1+ (1,0) [0|255] "" ORIN,RPI,TOOL
  SG_ B3 : 24|8@1+ (1,0) [0|255] "" ORIN,RPI,TOOL
  SG_ B4 : 32|8@1+ (1,0) [0|255] "" ORIN,RPI,TOOL
  SG_ B5 : 40|8@1+ (1,0) [0|255] "" ORIN,RPI,TOOL
  SG_ B6 : 48|8@1+ (1,0) [0|255] "" ORIN,RPI,TOOL
  SG_ B7 : 56|8@1+ (1,0) [0|255] "" ORIN,RPI,TOOL

BO_ 1184 FPGA_SENSORS_A: 8 FPGA
  SG_ SENSOR_1 : 0|16@1+ (1,0) [0|65535] "" ORIN,RPI,TOOL
  SG_ SENSOR_2 : 16|16@1+ (1,0) [0|65535] "" ORIN,RPI,TOOL
  SG_ SENSOR_3 : 32|16@1+ (1,0) [0|65535] "" ORIN,RPI,TOOL
  SG_ SENSOR_4 : 48|16@1+ (1,0) [0|65535] "" ORIN,RPI,TOOL

BO_ 1185 FPGA_SENSORS_B: 8 FPGA
  SG_ SENSOR_5 : 0|16@1+ (1,0) [0|65535] "" ORIN,RPI,TOOL
  SG_ SENSOR_6 : 16|16@1+ (1,0) [0|65535] "" ORIN,RPI,TOOL
  SG_ SENSOR_7 : 32|16@1+ (1,0) [0|65535] "" ORIN,RPI,TOOL
  SG_ SENSOR_8 : 48|16@1+ (1,0) [0|65535] "" ORIN,RPI,TOOL

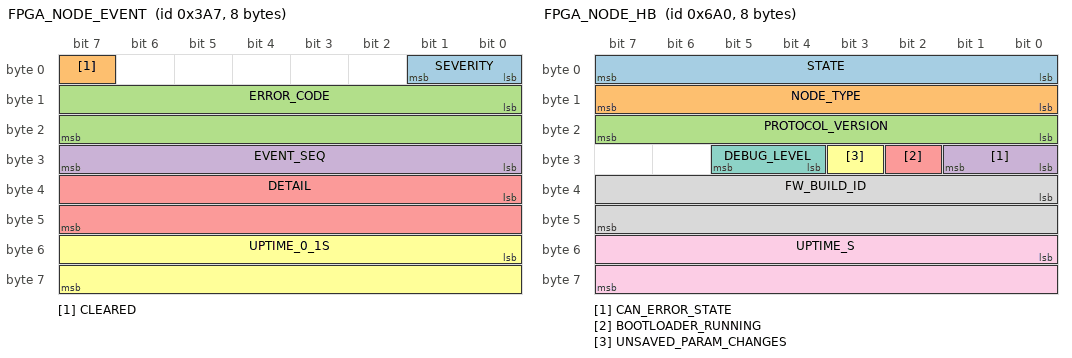
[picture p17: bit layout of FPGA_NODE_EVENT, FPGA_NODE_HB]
BO_ 935 FPGA_NODE_EVENT: 8 FPGA
  SG_ SEVERITY : 0|2@1+ (1,0) [0|3] "" ORIN,RPI,TOOL
  SG_ CLEARED : 7|1@1+ (1,0) [0|1] "" ORIN,RPI,TOOL
  SG_ ERROR_CODE : 8|16@1+ (1,0) [0|65535] "" ORIN,RPI,TOOL
  SG_ EVENT_SEQ : 24|8@1+ (1,0) [0|255] "" ORIN,RPI,TOOL
  SG_ DETAIL : 32|16@1+ (1,0) [0|65535] "" ORIN,RPI,TOOL
  SG_ UPTIME_0_1S : 48|16@1+ (0.1,0) [0|6553.5] "s" ORIN,RPI,TOOL

BO_ 1696 FPGA_NODE_HB: 8 FPGA
  SG_ STATE : 0|8@1+ (1,0) [0|5] "" ORIN,RPI,TOOL
  SG_ NODE_TYPE : 8|8@1+ (1,0) [0|5] "" ORIN,RPI,TOOL
  SG_ PROTOCOL_VERSION : 16|8@1+ (1,0) [0|255] "" ORIN,RPI,TOOL
  SG_ CAN_ERROR_STATE : 24|2@1+ (1,0) [0|2] "" ORIN,RPI,TOOL
  SG_ BOOTLOADER_RUNNING : 26|1@1+ (1,0) [0|1] "" ORIN,RPI,TOOL
  SG_ UNSAVED_PARAM_CHANGES : 27|1@1+ (1,0) [0|1] "" ORIN,RPI,TOOL
  SG_ DEBUG_LEVEL : 28|2@1+ (1,0) [0|3] "" ORIN,RPI,TOOL
  SG_ FW_BUILD_ID : 32|16@1+ (1,0) [0|65535] "" ORIN,RPI,TOOL
  SG_ UPTIME_S : 48|16@1+ (1,0) [0|65535] "s" ORIN,RPI,TOOL

BO_ 1531 NODE_ID_REQUEST: 8 ANY
  SG_ MAC : 0|48@1+ (1,0) [0|281474976710655] "" ORIN,RPI,TOOL
  SG_ NODE_TYPE : 48|8@1+ (1,0) [0|5] "" ORIN,RPI,TOOL
  SG_ HW_TARGET : 56|8@1+ (1,0) [0|255] "" ORIN,RPI,TOOL

BO_ 1528 NODE_ID_ASSIGN_ORIN: 8 ORIN
  SG_ MAC : 0|48@1+ (1,0) [0|281474976710655] "" ANY
  SG_ ASSIGNED_ID : 48|8@1+ (1,0) [0|31] "" ANY
  SG_ FLAGS : 56|8@1+ (1,0) [0|255] "" ANY

BO_ 1529 NODE_ID_ASSIGN_RPI: 8 RPI
  SG_ MAC : 0|48@1+ (1,0) [0|281474976710655] "" ANY
  SG_ ASSIGNED_ID : 48|8@1+ (1,0) [0|31] "" ANY
  SG_ FLAGS : 56|8@1+ (1,0) [0|255] "" ANY

BO_ 1530 NODE_ID_ASSIGN_TOOL: 8 TOOL
  SG_ MAC : 0|48@1+ (1,0) [0|281474976710655] "" ANY
  SG_ ASSIGNED_ID : 48|8@1+ (1,0) [0|31] "" ANY
  SG_ FLAGS : 56|8@1+ (1,0) [0|255] "" ANY

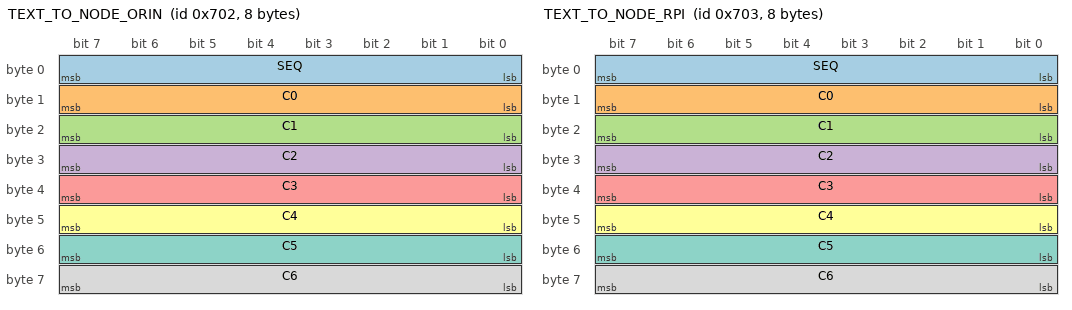
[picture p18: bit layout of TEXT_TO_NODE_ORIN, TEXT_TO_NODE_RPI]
BO_ 1794 TEXT_TO_NODE_ORIN: 8 ORIN
  SG_ SEQ : 0|8@1+ (1,0) [0|255] "" ANY
  SG_ C0 : 8|8@1+ (1,0) [0|255] "" ANY
  SG_ C1 : 16|8@1+ (1,0) [0|255] "" ANY
  SG_ C2 : 24|8@1+ (1,0) [0|255] "" ANY
  SG_ C3 : 32|8@1+ (1,0) [0|255] "" ANY
  SG_ C4 : 40|8@1+ (1,0) [0|255] "" ANY
  SG_ C5 : 48|8@1+ (1,0) [0|255] "" ANY
  SG_ C6 : 56|8@1+ (1,0) [0|255] "" ANY

BO_ 1795 TEXT_TO_NODE_RPI: 8 RPI
  SG_ SEQ : 0|8@1+ (1,0) [0|255] "" ANY
  SG_ C0 : 8|8@1+ (1,0) [0|255] "" ANY
  SG_ C1 : 16|8@1+ (1,0) [0|255] "" ANY
  SG_ C2 : 24|8@1+ (1,0) [0|255] "" ANY
  SG_ C3 : 32|8@1+ (1,0) [0|255] "" ANY
  SG_ C4 : 40|8@1+ (1,0) [0|255] "" ANY
  SG_ C5 : 48|8@1+ (1,0) [0|255] "" ANY
  SG_ C6 : 56|8@1+ (1,0) [0|255] "" ANY

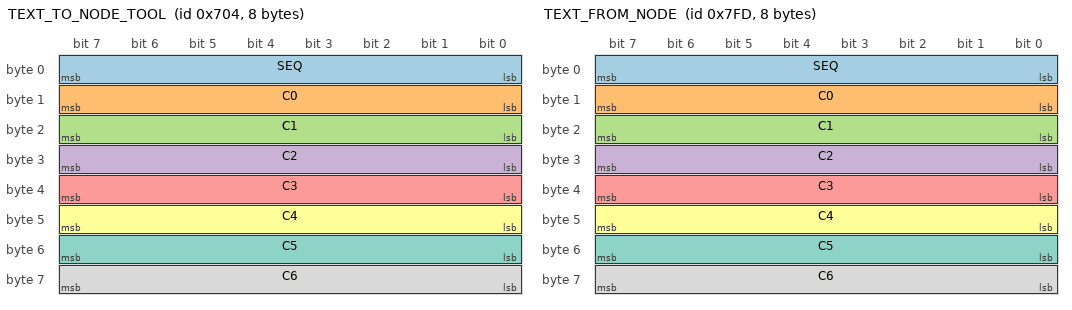
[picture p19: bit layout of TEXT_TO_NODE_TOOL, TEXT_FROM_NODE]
BO_ 1796 TEXT_TO_NODE_TOOL: 8 TOOL
  SG_ SEQ : 0|8@1+ (1,0) [0|255] "" ANY
  SG_ C0 : 8|8@1+ (1,0) [0|255] "" ANY
  SG_ C1 : 16|8@1+ (1,0) [0|255] "" ANY
  SG_ C2 : 24|8@1+ (1,0) [0|255] "" ANY
  SG_ C3 : 32|8@1+ (1,0) [0|255] "" ANY
  SG_ C4 : 40|8@1+ (1,0) [0|255] "" ANY
  SG_ C5 : 48|8@1+ (1,0) [0|255] "" ANY
  SG_ C6 : 56|8@1+ (1,0) [0|255] "" ANY

BO_ 2045 TEXT_FROM_NODE: 8 ANY
  SG_ SEQ : 0|8@1+ (1,0) [0|255] "" ORIN,RPI,TOOL
  SG_ C0 : 8|8@1+ (1,0) [0|255] "" ORIN,RPI,TOOL
  SG_ C1 : 16|8@1+ (1,0) [0|255] "" ORIN,RPI,TOOL
  SG_ C2 : 24|8@1+ (1,0) [0|255] "" ORIN,RPI,TOOL
  SG_ C3 : 32|8@1+ (1,0) [0|255] "" ORIN,RPI,TOOL
  SG_ C4 : 40|8@1+ (1,0) [0|255] "" ORIN,RPI,TOOL
  SG_ C5 : 48|8@1+ (1,0) [0|255] "" ORIN,RPI,TOOL
  SG_ C6 : 56|8@1+ (1,0) [0|255] "" ORIN,RPI,TOOL

BO_TX_BU_ 1 : ORIN,RPI,TOOL;
BO_TX_BU_ 2 : ORIN,RPI,TOOL;
BO_TX_BU_ 3 : ORIN,RPI,TOOL;
BO_TX_BU_ 4 : ORIN,RPI,TOOL;
BO_TX_BU_ 288 : ORIN,RPI,TOOL;
BO_TX_BU_ 1824 : ORIN,RPI,TOOL;
BO_TX_BU_ 296 : ORIN,RPI,TOOL;
BO_TX_BU_ 1832 : ORIN,RPI,TOOL;
BO_TX_BU_ 304 : ORIN,RPI,TOOL;
BO_TX_BU_ 1840 : ORIN,RPI,TOOL;
BO_TX_BU_ 312 : ORIN,RPI,TOOL;
BO_TX_BU_ 1848 : ORIN,RPI,TOOL;
BO_TX_BU_ 320 : ORIN,RPI,TOOL;
BO_TX_BU_ 1856 : ORIN,RPI,TOOL;
BO_TX_BU_ 328 : ORIN,RPI,TOOL;
BO_TX_BU_ 1864 : ORIN,RPI,TOOL;

CM_ "Anveshak rover CAN bus definitions. Classic CAN 2.0A, 11-bit IDs, 500 kbps, 80% sample point. ID = (class << 8) | (node << 3) | sub. See docs/architecture.md for the full design.";
CM_ BU_ ANY "Placeholder transmitter for ESTOP, which any node may send with an identical, fixed payload.";
CM_ BO_ 1794 "ORIN sends a short bench/debug text to a node: up to 7 ASCII characters (C0-C6, zero-padded) with a sequence number 1-255. This entry is the broadcast copy (node 0, every node); the same layout is used at 0x700 + 8 x node + 2 to address one node. Lowest-priority class, never used for control.";
CM_ BO_ 1795 "RPI sends a short bench/debug text to a node: up to 7 ASCII characters (C0-C6, zero-padded) with a sequence number 1-255. This entry is the broadcast copy (node 0, every node); the same layout is used at 0x700 + 8 x node + 3 to address one node. Lowest-priority class, never used for control.";
CM_ BO_ 1796 "TOOL sends a short bench/debug text to a node: up to 7 ASCII characters (C0-C6, zero-padded) with a sequence number 1-255. This entry is the broadcast copy (node 0, every node); the same layout is used at 0x700 + 8 x node + 4 to address one node. Lowest-priority class, never used for control.";
CM_ BO_ 2045 "Text from a node, sent at 0x700 + 8 x node + 5 (this entry is the layout template; node 31 never sends it). SEQ = the sequence number of the host text being echoed back (proof of receipt), or 0 for text the node sends on its own.";
CM_ BO_ 1531 "Unconfigured node (no stored node ID) asks for one. MAC is the board's factory MAC, least-significant byte first. HW_TARGET: 0 ESP32, 1 ESP32-S3. Sent with random jitter; no heartbeats until an ID is assigned.";
CM_ BO_ 1528 "ORIN assigns a node ID to the unconfigured board whose MAC matches. Sent by the allocator host (the master, or with no master the live host with the lowest tie-break).";
CM_ BO_ 1529 "RPI assigns a node ID to the unconfigured board whose MAC matches. Sent by the allocator host (the master, or with no master the live host with the lowest tie-break).";
CM_ BO_ 1530 "TOOL assigns a node ID to the unconfigured board whose MAC matches. Sent by the allocator host (the master, or with no master the live host with the lowest tie-break).";
CM_ BO_ 0 "Stop everything now. Byte 0 is always fixed at 0xE5 so simultaneous senders produce bit-identical frames.";
CM_ BO_ 1 "Clears the E-stop latch after operator action. Master only.";
CM_ BO_ 2 "Start of each 20 ms control cycle. Master only.";
CM_ BO_ 3 "Network management. COMMAND: 1 ARM, 2 DISARM, 3 RESET, 4 ENTER_BOOTLOADER, 5 FAULT_RESET. Master only.";
CM_ BO_ 4 "Sets the debug level of one node or all nodes. Master only.";
CM_ BO_ 8 "ORIN host heartbeat, 20 Hz. ROLE: 0 booting, 1 standby, 2 master, 3 observer. FLAGS bit0 autonomy ready, bit1 operator link up, bit2 E-stop latched, bit3 rover armed.";
CM_ BO_ 9 "Operator asked ORIN to take the lead.";
CM_ BO_ 16 "RPI host heartbeat, 20 Hz. ROLE: 0 booting, 1 standby, 2 master, 3 observer. FLAGS bit0 autonomy ready, bit1 operator link up, bit2 E-stop latched, bit3 rover armed.";
CM_ BO_ 17 "Operator asked RPI to take the lead.";
CM_ BO_ 24 "TOOL host heartbeat, 20 Hz. ROLE: 0 booting, 1 standby, 2 master, 3 observer. FLAGS bit0 autonomy ready, bit1 operator link up, bit2 E-stop latched, bit3 rover armed.";
CM_ BO_ 25 "Operator asked TOOL to take the lead.";
CM_ BO_ 288 "Command to DRIVE1 (node 4), 50 Hz, master only. MODE: 0 coast, 1 brake, 2 velocity, 3 open-loop duty (TARGET_A/B then read as 0.01% duty). Applied at the next SYNC.";
CM_ BO_ 544 "DRIVE1 fast feedback: state and fault flags, measured speed and current. 50 Hz. STATE: 0 BOOT, 1 DISARMED, 2 ARMED, 3 FAULT, 4 ESTOP, 5 BOOTLOADER. FAULT_FLAGS bit0 overcurrent A, 1 overcurrent B, 2 over-temp, 3 under-voltage, 4 encoder A fault, 5 encoder B fault, 6 command timeout, 7 E-stop latched.";
CM_ BO_ 545 "DRIVE1 raw encoder counts, 50 Hz. Counts per revolution is a node parameter.";
CM_ BO_ 800 "DRIVE1 slow telemetry page 0. 10 Hz (1 Hz at debug level 0).";
CM_ BO_ 801 "DRIVE1 slow telemetry page 1. 10 Hz (1 Hz at debug level 0). LAST_RESET_CAUSE: 0 power-on, 1 brown-out, 2 watchdog, 3 software, 4 pin.";
CM_ BO_ 802 "DRIVE1 channel A PID internals. Only sent at debug level 2 (10 Hz) or 3 (50 Hz).";
CM_ BO_ 803 "DRIVE1 channel B PID internals. Only sent at debug level 2 (10 Hz) or 3 (50 Hz).";
CM_ BO_ 807 "DRIVE1 event report, sent edge-triggered, rate-limited to one per code per second. SEVERITY: 0 info, 1 warning, 2 error, 3 critical. CLEARED set when the condition ends.";
CM_ BO_ 1312 "ORIN -> DRIVE1 parameter/service request. OPCODE: 1 GET, 2 SET, 3 SAVE, 4 RESTORE_DEFAULTS, 5 INFO, 6 LOG_READ, 7 LOG_CLEAR. VALUE_RAW holds the SET value, raw bits, reinterpreted per the parameter's type.";
CM_ BO_ 1313 "RPI -> DRIVE1 parameter/service request. OPCODE: 1 GET, 2 SET, 3 SAVE, 4 RESTORE_DEFAULTS, 5 INFO, 6 LOG_READ, 7 LOG_CLEAR. VALUE_RAW holds the SET value, raw bits, reinterpreted per the parameter's type.";
CM_ BO_ 1314 "TOOL -> DRIVE1 parameter/service request. OPCODE: 1 GET, 2 SET, 3 SAVE, 4 RESTORE_DEFAULTS, 5 INFO, 6 LOG_READ, 7 LOG_CLEAR. VALUE_RAW holds the SET value, raw bits, reinterpreted per the parameter's type.";
CM_ BO_ 1316 "DRIVE1 -> ORIN parameter/service response. STATUS: 0 OK, 1 bad index, 2 out of range, 3 not allowed while armed, 4 flash error. VALUE_RAW holds the current value, raw bits.";
CM_ BO_ 1317 "DRIVE1 -> RPI parameter/service response. STATUS: 0 OK, 1 bad index, 2 out of range, 3 not allowed while armed, 4 flash error. VALUE_RAW holds the current value, raw bits.";
CM_ BO_ 1318 "DRIVE1 -> TOOL parameter/service response. STATUS: 0 OK, 1 bad index, 2 out of range, 3 not allowed while armed, 4 flash error. VALUE_RAW holds the current value, raw bits.";
CM_ BO_ 1568 "DRIVE1 heartbeat, 10 Hz. NODE_TYPE: 1 drive, 2 arm, 3 science, 4 FPGA, 5 power. CAN_ERROR_STATE: 0 active, 1 passive, 2 recovered from bus-off.";
CM_ BO_ 1824 "Host -> DRIVE1 bootloader / firmware transfer (ISO-TP). Only while DRIVE1 is disarmed.";
CM_ BO_ 1825 "DRIVE1 -> host bootloader / firmware transfer (ISO-TP).";
CM_ BO_ 296 "Command to DRIVE2 (node 5), 50 Hz, master only. MODE: 0 coast, 1 brake, 2 velocity, 3 open-loop duty (TARGET_A/B then read as 0.01% duty). Applied at the next SYNC.";
CM_ BO_ 552 "DRIVE2 fast feedback: state and fault flags, measured speed and current. 50 Hz. STATE: 0 BOOT, 1 DISARMED, 2 ARMED, 3 FAULT, 4 ESTOP, 5 BOOTLOADER. FAULT_FLAGS bit0 overcurrent A, 1 overcurrent B, 2 over-temp, 3 under-voltage, 4 encoder A fault, 5 encoder B fault, 6 command timeout, 7 E-stop latched.";
CM_ BO_ 553 "DRIVE2 raw encoder counts, 50 Hz. Counts per revolution is a node parameter.";
CM_ BO_ 808 "DRIVE2 slow telemetry page 0. 10 Hz (1 Hz at debug level 0).";
CM_ BO_ 809 "DRIVE2 slow telemetry page 1. 10 Hz (1 Hz at debug level 0). LAST_RESET_CAUSE: 0 power-on, 1 brown-out, 2 watchdog, 3 software, 4 pin.";
CM_ BO_ 810 "DRIVE2 channel A PID internals. Only sent at debug level 2 (10 Hz) or 3 (50 Hz).";
CM_ BO_ 811 "DRIVE2 channel B PID internals. Only sent at debug level 2 (10 Hz) or 3 (50 Hz).";
CM_ BO_ 815 "DRIVE2 event report, sent edge-triggered, rate-limited to one per code per second. SEVERITY: 0 info, 1 warning, 2 error, 3 critical. CLEARED set when the condition ends.";
CM_ BO_ 1320 "ORIN -> DRIVE2 parameter/service request. OPCODE: 1 GET, 2 SET, 3 SAVE, 4 RESTORE_DEFAULTS, 5 INFO, 6 LOG_READ, 7 LOG_CLEAR. VALUE_RAW holds the SET value, raw bits, reinterpreted per the parameter's type.";
CM_ BO_ 1321 "RPI -> DRIVE2 parameter/service request. OPCODE: 1 GET, 2 SET, 3 SAVE, 4 RESTORE_DEFAULTS, 5 INFO, 6 LOG_READ, 7 LOG_CLEAR. VALUE_RAW holds the SET value, raw bits, reinterpreted per the parameter's type.";
CM_ BO_ 1322 "TOOL -> DRIVE2 parameter/service request. OPCODE: 1 GET, 2 SET, 3 SAVE, 4 RESTORE_DEFAULTS, 5 INFO, 6 LOG_READ, 7 LOG_CLEAR. VALUE_RAW holds the SET value, raw bits, reinterpreted per the parameter's type.";
CM_ BO_ 1324 "DRIVE2 -> ORIN parameter/service response. STATUS: 0 OK, 1 bad index, 2 out of range, 3 not allowed while armed, 4 flash error. VALUE_RAW holds the current value, raw bits.";
CM_ BO_ 1325 "DRIVE2 -> RPI parameter/service response. STATUS: 0 OK, 1 bad index, 2 out of range, 3 not allowed while armed, 4 flash error. VALUE_RAW holds the current value, raw bits.";
CM_ BO_ 1326 "DRIVE2 -> TOOL parameter/service response. STATUS: 0 OK, 1 bad index, 2 out of range, 3 not allowed while armed, 4 flash error. VALUE_RAW holds the current value, raw bits.";
CM_ BO_ 1576 "DRIVE2 heartbeat, 10 Hz. NODE_TYPE: 1 drive, 2 arm, 3 science, 4 FPGA, 5 power. CAN_ERROR_STATE: 0 active, 1 passive, 2 recovered from bus-off.";
CM_ BO_ 1832 "Host -> DRIVE2 bootloader / firmware transfer (ISO-TP). Only while DRIVE2 is disarmed.";
CM_ BO_ 1833 "DRIVE2 -> host bootloader / firmware transfer (ISO-TP).";
CM_ BO_ 304 "Command to DRIVE3 (node 6), 50 Hz, master only. MODE: 0 coast, 1 brake, 2 velocity, 3 open-loop duty (TARGET_A/B then read as 0.01% duty). Applied at the next SYNC.";
CM_ BO_ 560 "DRIVE3 fast feedback: state and fault flags, measured speed and current. 50 Hz. STATE: 0 BOOT, 1 DISARMED, 2 ARMED, 3 FAULT, 4 ESTOP, 5 BOOTLOADER. FAULT_FLAGS bit0 overcurrent A, 1 overcurrent B, 2 over-temp, 3 under-voltage, 4 encoder A fault, 5 encoder B fault, 6 command timeout, 7 E-stop latched.";
CM_ BO_ 561 "DRIVE3 raw encoder counts, 50 Hz. Counts per revolution is a node parameter.";
CM_ BO_ 816 "DRIVE3 slow telemetry page 0. 10 Hz (1 Hz at debug level 0).";
CM_ BO_ 817 "DRIVE3 slow telemetry page 1. 10 Hz (1 Hz at debug level 0). LAST_RESET_CAUSE: 0 power-on, 1 brown-out, 2 watchdog, 3 software, 4 pin.";
CM_ BO_ 818 "DRIVE3 channel A PID internals. Only sent at debug level 2 (10 Hz) or 3 (50 Hz).";
CM_ BO_ 819 "DRIVE3 channel B PID internals. Only sent at debug level 2 (10 Hz) or 3 (50 Hz).";
CM_ BO_ 823 "DRIVE3 event report, sent edge-triggered, rate-limited to one per code per second. SEVERITY: 0 info, 1 warning, 2 error, 3 critical. CLEARED set when the condition ends.";
CM_ BO_ 1328 "ORIN -> DRIVE3 parameter/service request. OPCODE: 1 GET, 2 SET, 3 SAVE, 4 RESTORE_DEFAULTS, 5 INFO, 6 LOG_READ, 7 LOG_CLEAR. VALUE_RAW holds the SET value, raw bits, reinterpreted per the parameter's type.";
CM_ BO_ 1329 "RPI -> DRIVE3 parameter/service request. OPCODE: 1 GET, 2 SET, 3 SAVE, 4 RESTORE_DEFAULTS, 5 INFO, 6 LOG_READ, 7 LOG_CLEAR. VALUE_RAW holds the SET value, raw bits, reinterpreted per the parameter's type.";
CM_ BO_ 1330 "TOOL -> DRIVE3 parameter/service request. OPCODE: 1 GET, 2 SET, 3 SAVE, 4 RESTORE_DEFAULTS, 5 INFO, 6 LOG_READ, 7 LOG_CLEAR. VALUE_RAW holds the SET value, raw bits, reinterpreted per the parameter's type.";
CM_ BO_ 1332 "DRIVE3 -> ORIN parameter/service response. STATUS: 0 OK, 1 bad index, 2 out of range, 3 not allowed while armed, 4 flash error. VALUE_RAW holds the current value, raw bits.";
CM_ BO_ 1333 "DRIVE3 -> RPI parameter/service response. STATUS: 0 OK, 1 bad index, 2 out of range, 3 not allowed while armed, 4 flash error. VALUE_RAW holds the current value, raw bits.";
CM_ BO_ 1334 "DRIVE3 -> TOOL parameter/service response. STATUS: 0 OK, 1 bad index, 2 out of range, 3 not allowed while armed, 4 flash error. VALUE_RAW holds the current value, raw bits.";
CM_ BO_ 1584 "DRIVE3 heartbeat, 10 Hz. NODE_TYPE: 1 drive, 2 arm, 3 science, 4 FPGA, 5 power. CAN_ERROR_STATE: 0 active, 1 passive, 2 recovered from bus-off.";
CM_ BO_ 1840 "Host -> DRIVE3 bootloader / firmware transfer (ISO-TP). Only while DRIVE3 is disarmed.";
CM_ BO_ 1841 "DRIVE3 -> host bootloader / firmware transfer (ISO-TP).";
CM_ BO_ 312 "Command to DRIVE4 (node 7), 50 Hz, master only. MODE: 0 coast, 1 brake, 2 velocity, 3 open-loop duty (TARGET_A/B then read as 0.01% duty). Applied at the next SYNC.";
CM_ BO_ 568 "DRIVE4 fast feedback: state and fault flags, measured speed and current. 50 Hz. STATE: 0 BOOT, 1 DISARMED, 2 ARMED, 3 FAULT, 4 ESTOP, 5 BOOTLOADER. FAULT_FLAGS bit0 overcurrent A, 1 overcurrent B, 2 over-temp, 3 under-voltage, 4 encoder A fault, 5 encoder B fault, 6 command timeout, 7 E-stop latched.";
CM_ BO_ 569 "DRIVE4 raw encoder counts, 50 Hz. Counts per revolution is a node parameter.";
CM_ BO_ 824 "DRIVE4 slow telemetry page 0. 10 Hz (1 Hz at debug level 0).";
CM_ BO_ 825 "DRIVE4 slow telemetry page 1. 10 Hz (1 Hz at debug level 0). LAST_RESET_CAUSE: 0 power-on, 1 brown-out, 2 watchdog, 3 software, 4 pin.";
CM_ BO_ 826 "DRIVE4 channel A PID internals. Only sent at debug level 2 (10 Hz) or 3 (50 Hz).";
CM_ BO_ 827 "DRIVE4 channel B PID internals. Only sent at debug level 2 (10 Hz) or 3 (50 Hz).";
CM_ BO_ 831 "DRIVE4 event report, sent edge-triggered, rate-limited to one per code per second. SEVERITY: 0 info, 1 warning, 2 error, 3 critical. CLEARED set when the condition ends.";
CM_ BO_ 1336 "ORIN -> DRIVE4 parameter/service request. OPCODE: 1 GET, 2 SET, 3 SAVE, 4 RESTORE_DEFAULTS, 5 INFO, 6 LOG_READ, 7 LOG_CLEAR. VALUE_RAW holds the SET value, raw bits, reinterpreted per the parameter's type.";
CM_ BO_ 1337 "RPI -> DRIVE4 parameter/service request. OPCODE: 1 GET, 2 SET, 3 SAVE, 4 RESTORE_DEFAULTS, 5 INFO, 6 LOG_READ, 7 LOG_CLEAR. VALUE_RAW holds the SET value, raw bits, reinterpreted per the parameter's type.";
CM_ BO_ 1338 "TOOL -> DRIVE4 parameter/service request. OPCODE: 1 GET, 2 SET, 3 SAVE, 4 RESTORE_DEFAULTS, 5 INFO, 6 LOG_READ, 7 LOG_CLEAR. VALUE_RAW holds the SET value, raw bits, reinterpreted per the parameter's type.";
CM_ BO_ 1340 "DRIVE4 -> ORIN parameter/service response. STATUS: 0 OK, 1 bad index, 2 out of range, 3 not allowed while armed, 4 flash error. VALUE_RAW holds the current value, raw bits.";
CM_ BO_ 1341 "DRIVE4 -> RPI parameter/service response. STATUS: 0 OK, 1 bad index, 2 out of range, 3 not allowed while armed, 4 flash error. VALUE_RAW holds the current value, raw bits.";
CM_ BO_ 1342 "DRIVE4 -> TOOL parameter/service response. STATUS: 0 OK, 1 bad index, 2 out of range, 3 not allowed while armed, 4 flash error. VALUE_RAW holds the current value, raw bits.";
CM_ BO_ 1592 "DRIVE4 heartbeat, 10 Hz. NODE_TYPE: 1 drive, 2 arm, 3 science, 4 FPGA, 5 power. CAN_ERROR_STATE: 0 active, 1 passive, 2 recovered from bus-off.";
CM_ BO_ 1848 "Host -> DRIVE4 bootloader / firmware transfer (ISO-TP). Only while DRIVE4 is disarmed.";
CM_ BO_ 1849 "DRIVE4 -> host bootloader / firmware transfer (ISO-TP).";
CM_ BO_ 320 "Command to DRIVE5 (node 8), 50 Hz, master only. MODE: 0 coast, 1 brake, 2 velocity, 3 open-loop duty (TARGET_A/B then read as 0.01% duty). Applied at the next SYNC.";
CM_ BO_ 576 "DRIVE5 fast feedback: state and fault flags, measured speed and current. 50 Hz. STATE: 0 BOOT, 1 DISARMED, 2 ARMED, 3 FAULT, 4 ESTOP, 5 BOOTLOADER. FAULT_FLAGS bit0 overcurrent A, 1 overcurrent B, 2 over-temp, 3 under-voltage, 4 encoder A fault, 5 encoder B fault, 6 command timeout, 7 E-stop latched.";
CM_ BO_ 577 "DRIVE5 raw encoder counts, 50 Hz. Counts per revolution is a node parameter.";
CM_ BO_ 832 "DRIVE5 slow telemetry page 0. 10 Hz (1 Hz at debug level 0).";
CM_ BO_ 833 "DRIVE5 slow telemetry page 1. 10 Hz (1 Hz at debug level 0). LAST_RESET_CAUSE: 0 power-on, 1 brown-out, 2 watchdog, 3 software, 4 pin.";
CM_ BO_ 834 "DRIVE5 channel A PID internals. Only sent at debug level 2 (10 Hz) or 3 (50 Hz).";
CM_ BO_ 835 "DRIVE5 channel B PID internals. Only sent at debug level 2 (10 Hz) or 3 (50 Hz).";
CM_ BO_ 839 "DRIVE5 event report, sent edge-triggered, rate-limited to one per code per second. SEVERITY: 0 info, 1 warning, 2 error, 3 critical. CLEARED set when the condition ends.";
CM_ BO_ 1344 "ORIN -> DRIVE5 parameter/service request. OPCODE: 1 GET, 2 SET, 3 SAVE, 4 RESTORE_DEFAULTS, 5 INFO, 6 LOG_READ, 7 LOG_CLEAR. VALUE_RAW holds the SET value, raw bits, reinterpreted per the parameter's type.";
CM_ BO_ 1345 "RPI -> DRIVE5 parameter/service request. OPCODE: 1 GET, 2 SET, 3 SAVE, 4 RESTORE_DEFAULTS, 5 INFO, 6 LOG_READ, 7 LOG_CLEAR. VALUE_RAW holds the SET value, raw bits, reinterpreted per the parameter's type.";
CM_ BO_ 1346 "TOOL -> DRIVE5 parameter/service request. OPCODE: 1 GET, 2 SET, 3 SAVE, 4 RESTORE_DEFAULTS, 5 INFO, 6 LOG_READ, 7 LOG_CLEAR. VALUE_RAW holds the SET value, raw bits, reinterpreted per the parameter's type.";
CM_ BO_ 1348 "DRIVE5 -> ORIN parameter/service response. STATUS: 0 OK, 1 bad index, 2 out of range, 3 not allowed while armed, 4 flash error. VALUE_RAW holds the current value, raw bits.";
CM_ BO_ 1349 "DRIVE5 -> RPI parameter/service response. STATUS: 0 OK, 1 bad index, 2 out of range, 3 not allowed while armed, 4 flash error. VALUE_RAW holds the current value, raw bits.";
CM_ BO_ 1350 "DRIVE5 -> TOOL parameter/service response. STATUS: 0 OK, 1 bad index, 2 out of range, 3 not allowed while armed, 4 flash error. VALUE_RAW holds the current value, raw bits.";
CM_ BO_ 1600 "DRIVE5 heartbeat, 10 Hz. NODE_TYPE: 1 drive, 2 arm, 3 science, 4 FPGA, 5 power. CAN_ERROR_STATE: 0 active, 1 passive, 2 recovered from bus-off.";
CM_ BO_ 1856 "Host -> DRIVE5 bootloader / firmware transfer (ISO-TP). Only while DRIVE5 is disarmed.";
CM_ BO_ 1857 "DRIVE5 -> host bootloader / firmware transfer (ISO-TP).";
CM_ BO_ 328 "Command to DRIVE6 (node 9), 50 Hz, master only. MODE: 0 coast, 1 brake, 2 velocity, 3 open-loop duty (TARGET_A/B then read as 0.01% duty). Applied at the next SYNC.";
CM_ BO_ 584 "DRIVE6 fast feedback: state and fault flags, measured speed and current. 50 Hz. STATE: 0 BOOT, 1 DISARMED, 2 ARMED, 3 FAULT, 4 ESTOP, 5 BOOTLOADER. FAULT_FLAGS bit0 overcurrent A, 1 overcurrent B, 2 over-temp, 3 under-voltage, 4 encoder A fault, 5 encoder B fault, 6 command timeout, 7 E-stop latched.";
CM_ BO_ 585 "DRIVE6 raw encoder counts, 50 Hz. Counts per revolution is a node parameter.";
CM_ BO_ 840 "DRIVE6 slow telemetry page 0. 10 Hz (1 Hz at debug level 0).";
CM_ BO_ 841 "DRIVE6 slow telemetry page 1. 10 Hz (1 Hz at debug level 0). LAST_RESET_CAUSE: 0 power-on, 1 brown-out, 2 watchdog, 3 software, 4 pin.";
CM_ BO_ 842 "DRIVE6 channel A PID internals. Only sent at debug level 2 (10 Hz) or 3 (50 Hz).";
CM_ BO_ 843 "DRIVE6 channel B PID internals. Only sent at debug level 2 (10 Hz) or 3 (50 Hz).";
CM_ BO_ 847 "DRIVE6 event report, sent edge-triggered, rate-limited to one per code per second. SEVERITY: 0 info, 1 warning, 2 error, 3 critical. CLEARED set when the condition ends.";
CM_ BO_ 1352 "ORIN -> DRIVE6 parameter/service request. OPCODE: 1 GET, 2 SET, 3 SAVE, 4 RESTORE_DEFAULTS, 5 INFO, 6 LOG_READ, 7 LOG_CLEAR. VALUE_RAW holds the SET value, raw bits, reinterpreted per the parameter's type.";
CM_ BO_ 1353 "RPI -> DRIVE6 parameter/service request. OPCODE: 1 GET, 2 SET, 3 SAVE, 4 RESTORE_DEFAULTS, 5 INFO, 6 LOG_READ, 7 LOG_CLEAR. VALUE_RAW holds the SET value, raw bits, reinterpreted per the parameter's type.";
CM_ BO_ 1354 "TOOL -> DRIVE6 parameter/service request. OPCODE: 1 GET, 2 SET, 3 SAVE, 4 RESTORE_DEFAULTS, 5 INFO, 6 LOG_READ, 7 LOG_CLEAR. VALUE_RAW holds the SET value, raw bits, reinterpreted per the parameter's type.";
CM_ BO_ 1356 "DRIVE6 -> ORIN parameter/service response. STATUS: 0 OK, 1 bad index, 2 out of range, 3 not allowed while armed, 4 flash error. VALUE_RAW holds the current value, raw bits.";
CM_ BO_ 1357 "DRIVE6 -> RPI parameter/service response. STATUS: 0 OK, 1 bad index, 2 out of range, 3 not allowed while armed, 4 flash error. VALUE_RAW holds the current value, raw bits.";
CM_ BO_ 1358 "DRIVE6 -> TOOL parameter/service response. STATUS: 0 OK, 1 bad index, 2 out of range, 3 not allowed while armed, 4 flash error. VALUE_RAW holds the current value, raw bits.";
CM_ BO_ 1608 "DRIVE6 heartbeat, 10 Hz. NODE_TYPE: 1 drive, 2 arm, 3 science, 4 FPGA, 5 power. CAN_ERROR_STATE: 0 active, 1 passive, 2 recovered from bus-off.";
CM_ BO_ 1864 "Host -> DRIVE6 bootloader / firmware transfer (ISO-TP). Only while DRIVE6 is disarmed.";
CM_ BO_ 1865 "DRIVE6 -> host bootloader / firmware transfer (ISO-TP).";
CM_ BO_ 1184 "FPGA sensors 1-4, 50 Hz. Per-sensor scaling is applied by the host from the params table.";
CM_ BO_ 1185 "FPGA sensors 5-8, 50 Hz. Per-sensor scaling is applied by the host from the params table.";
CM_ BO_ 935 "FPGA event report. SEVERITY: 0 info, 1 warning, 2 error, 3 critical.";
CM_ BO_ 1696 "FPGA heartbeat, 10 Hz.";

BA_DEF_ "ProtocolVersion" INT 0 65535;
BA_DEF_ BO_ "GenMsgCycleTime" INT 0 100000;
BA_DEF_DEF_ "ProtocolVersion" 1;
BA_DEF_DEF_ "GenMsgCycleTime" 0;
BA_ "GenMsgCycleTime" BO_ 2 20;
BA_ "GenMsgCycleTime" BO_ 8 50;
BA_ "GenMsgCycleTime" BO_ 16 50;
BA_ "GenMsgCycleTime" BO_ 24 50;
BA_ "GenMsgCycleTime" BO_ 288 20;
BA_ "GenMsgCycleTime" BO_ 544 20;
BA_ "GenMsgCycleTime" BO_ 545 20;
BA_ "GenMsgCycleTime" BO_ 800 100;
BA_ "GenMsgCycleTime" BO_ 801 100;
BA_ "GenMsgCycleTime" BO_ 802 20;
BA_ "GenMsgCycleTime" BO_ 803 20;
BA_ "GenMsgCycleTime" BO_ 1568 100;
BA_ "GenMsgCycleTime" BO_ 296 20;
BA_ "GenMsgCycleTime" BO_ 552 20;
BA_ "GenMsgCycleTime" BO_ 553 20;
BA_ "GenMsgCycleTime" BO_ 808 100;
BA_ "GenMsgCycleTime" BO_ 809 100;
BA_ "GenMsgCycleTime" BO_ 810 20;
BA_ "GenMsgCycleTime" BO_ 811 20;
BA_ "GenMsgCycleTime" BO_ 1576 100;
BA_ "GenMsgCycleTime" BO_ 304 20;
BA_ "GenMsgCycleTime" BO_ 560 20;
BA_ "GenMsgCycleTime" BO_ 561 20;
BA_ "GenMsgCycleTime" BO_ 816 100;
BA_ "GenMsgCycleTime" BO_ 817 100;
BA_ "GenMsgCycleTime" BO_ 818 20;
BA_ "GenMsgCycleTime" BO_ 819 20;
BA_ "GenMsgCycleTime" BO_ 1584 100;
BA_ "GenMsgCycleTime" BO_ 312 20;
BA_ "GenMsgCycleTime" BO_ 568 20;
BA_ "GenMsgCycleTime" BO_ 569 20;
BA_ "GenMsgCycleTime" BO_ 824 100;
BA_ "GenMsgCycleTime" BO_ 825 100;
BA_ "GenMsgCycleTime" BO_ 826 20;
BA_ "GenMsgCycleTime" BO_ 827 20;
BA_ "GenMsgCycleTime" BO_ 1592 100;
BA_ "GenMsgCycleTime" BO_ 320 20;
BA_ "GenMsgCycleTime" BO_ 576 20;
BA_ "GenMsgCycleTime" BO_ 577 20;
BA_ "GenMsgCycleTime" BO_ 832 100;
BA_ "GenMsgCycleTime" BO_ 833 100;
BA_ "GenMsgCycleTime" BO_ 834 20;
BA_ "GenMsgCycleTime" BO_ 835 20;
BA_ "GenMsgCycleTime" BO_ 1600 100;
BA_ "GenMsgCycleTime" BO_ 328 20;
BA_ "GenMsgCycleTime" BO_ 584 20;
BA_ "GenMsgCycleTime" BO_ 585 20;
BA_ "GenMsgCycleTime" BO_ 840 100;
BA_ "GenMsgCycleTime" BO_ 841 100;
BA_ "GenMsgCycleTime" BO_ 842 20;
BA_ "GenMsgCycleTime" BO_ 843 20;
BA_ "GenMsgCycleTime" BO_ 1608 100;
BA_ "GenMsgCycleTime" BO_ 1184 20;
BA_ "GenMsgCycleTime" BO_ 1185 20;
BA_ "GenMsgCycleTime" BO_ 1696 100;

VAL_ 3 COMMAND 1 "ARM" 2 "DISARM" 3 "RESET" 4 "ENTER_BOOTLOADER" 5 "FAULT_RESET";
VAL_ 8 ROLE 0 "BOOTING" 1 "STANDBY" 2 "MASTER" 3 "OBSERVER";
VAL_ 16 ROLE 0 "BOOTING" 1 "STANDBY" 2 "MASTER" 3 "OBSERVER";
VAL_ 24 ROLE 0 "BOOTING" 1 "STANDBY" 2 "MASTER" 3 "OBSERVER";
VAL_ 288 MODE 0 "COAST" 1 "BRAKE" 2 "VELOCITY" 3 "OPEN_LOOP_DUTY";
VAL_ 544 STATE 0 "BOOT" 1 "DISARMED" 2 "ARMED" 3 "FAULT" 4 "ESTOP" 5 "BOOTLOADER";
VAL_ 1568 STATE 0 "BOOT" 1 "DISARMED" 2 "ARMED" 3 "FAULT" 4 "ESTOP" 5 "BOOTLOADER";
VAL_ 1568 NODE_TYPE 1 "DRIVE" 2 "ARM" 3 "SCIENCE" 4 "FPGA" 5 "POWER";
VAL_ 807 SEVERITY 0 "INFO" 1 "WARNING" 2 "ERROR" 3 "CRITICAL";
VAL_ 801 LAST_RESET_CAUSE 0 "POWER_ON" 1 "BROWN_OUT" 2 "WATCHDOG" 3 "SOFTWARE" 4 "PIN";
VAL_ 1316 STATUS 0 "OK" 1 "BAD_INDEX" 2 "OUT_OF_RANGE" 3 "NOT_ALLOWED_WHILE_ARMED" 4 "FLASH_ERROR";
VAL_ 1317 STATUS 0 "OK" 1 "BAD_INDEX" 2 "OUT_OF_RANGE" 3 "NOT_ALLOWED_WHILE_ARMED" 4 "FLASH_ERROR";
VAL_ 1318 STATUS 0 "OK" 1 "BAD_INDEX" 2 "OUT_OF_RANGE" 3 "NOT_ALLOWED_WHILE_ARMED" 4 "FLASH_ERROR";
VAL_ 296 MODE 0 "COAST" 1 "BRAKE" 2 "VELOCITY" 3 "OPEN_LOOP_DUTY";
VAL_ 552 STATE 0 "BOOT" 1 "DISARMED" 2 "ARMED" 3 "FAULT" 4 "ESTOP" 5 "BOOTLOADER";
VAL_ 1576 STATE 0 "BOOT" 1 "DISARMED" 2 "ARMED" 3 "FAULT" 4 "ESTOP" 5 "BOOTLOADER";
VAL_ 1576 NODE_TYPE 1 "DRIVE" 2 "ARM" 3 "SCIENCE" 4 "FPGA" 5 "POWER";
VAL_ 815 SEVERITY 0 "INFO" 1 "WARNING" 2 "ERROR" 3 "CRITICAL";
VAL_ 809 LAST_RESET_CAUSE 0 "POWER_ON" 1 "BROWN_OUT" 2 "WATCHDOG" 3 "SOFTWARE" 4 "PIN";
VAL_ 1324 STATUS 0 "OK" 1 "BAD_INDEX" 2 "OUT_OF_RANGE" 3 "NOT_ALLOWED_WHILE_ARMED" 4 "FLASH_ERROR";
VAL_ 1325 STATUS 0 "OK" 1 "BAD_INDEX" 2 "OUT_OF_RANGE" 3 "NOT_ALLOWED_WHILE_ARMED" 4 "FLASH_ERROR";
VAL_ 1326 STATUS 0 "OK" 1 "BAD_INDEX" 2 "OUT_OF_RANGE" 3 "NOT_ALLOWED_WHILE_ARMED" 4 "FLASH_ERROR";
VAL_ 304 MODE 0 "COAST" 1 "BRAKE" 2 "VELOCITY" 3 "OPEN_LOOP_DUTY";
VAL_ 560 STATE 0 "BOOT" 1 "DISARMED" 2 "ARMED" 3 "FAULT" 4 "ESTOP" 5 "BOOTLOADER";
VAL_ 1584 STATE 0 "BOOT" 1 "DISARMED" 2 "ARMED" 3 "FAULT" 4 "ESTOP" 5 "BOOTLOADER";
VAL_ 1584 NODE_TYPE 1 "DRIVE" 2 "ARM" 3 "SCIENCE" 4 "FPGA" 5 "POWER";
VAL_ 823 SEVERITY 0 "INFO" 1 "WARNING" 2 "ERROR" 3 "CRITICAL";
VAL_ 817 LAST_RESET_CAUSE 0 "POWER_ON" 1 "BROWN_OUT" 2 "WATCHDOG" 3 "SOFTWARE" 4 "PIN";
VAL_ 1332 STATUS 0 "OK" 1 "BAD_INDEX" 2 "OUT_OF_RANGE" 3 "NOT_ALLOWED_WHILE_ARMED" 4 "FLASH_ERROR";
VAL_ 1333 STATUS 0 "OK" 1 "BAD_INDEX" 2 "OUT_OF_RANGE" 3 "NOT_ALLOWED_WHILE_ARMED" 4 "FLASH_ERROR";
VAL_ 1334 STATUS 0 "OK" 1 "BAD_INDEX" 2 "OUT_OF_RANGE" 3 "NOT_ALLOWED_WHILE_ARMED" 4 "FLASH_ERROR";
VAL_ 312 MODE 0 "COAST" 1 "BRAKE" 2 "VELOCITY" 3 "OPEN_LOOP_DUTY";
VAL_ 568 STATE 0 "BOOT" 1 "DISARMED" 2 "ARMED" 3 "FAULT" 4 "ESTOP" 5 "BOOTLOADER";
VAL_ 1592 STATE 0 "BOOT" 1 "DISARMED" 2 "ARMED" 3 "FAULT" 4 "ESTOP" 5 "BOOTLOADER";
VAL_ 1592 NODE_TYPE 1 "DRIVE" 2 "ARM" 3 "SCIENCE" 4 "FPGA" 5 "POWER";
VAL_ 831 SEVERITY 0 "INFO" 1 "WARNING" 2 "ERROR" 3 "CRITICAL";
VAL_ 825 LAST_RESET_CAUSE 0 "POWER_ON" 1 "BROWN_OUT" 2 "WATCHDOG" 3 "SOFTWARE" 4 "PIN";
VAL_ 1340 STATUS 0 "OK" 1 "BAD_INDEX" 2 "OUT_OF_RANGE" 3 "NOT_ALLOWED_WHILE_ARMED" 4 "FLASH_ERROR";
VAL_ 1341 STATUS 0 "OK" 1 "BAD_INDEX" 2 "OUT_OF_RANGE" 3 "NOT_ALLOWED_WHILE_ARMED" 4 "FLASH_ERROR";
VAL_ 1342 STATUS 0 "OK" 1 "BAD_INDEX" 2 "OUT_OF_RANGE" 3 "NOT_ALLOWED_WHILE_ARMED" 4 "FLASH_ERROR";
VAL_ 320 MODE 0 "COAST" 1 "BRAKE" 2 "VELOCITY" 3 "OPEN_LOOP_DUTY";
VAL_ 576 STATE 0 "BOOT" 1 "DISARMED" 2 "ARMED" 3 "FAULT" 4 "ESTOP" 5 "BOOTLOADER";
VAL_ 1600 STATE 0 "BOOT" 1 "DISARMED" 2 "ARMED" 3 "FAULT" 4 "ESTOP" 5 "BOOTLOADER";
VAL_ 1600 NODE_TYPE 1 "DRIVE" 2 "ARM" 3 "SCIENCE" 4 "FPGA" 5 "POWER";
VAL_ 839 SEVERITY 0 "INFO" 1 "WARNING" 2 "ERROR" 3 "CRITICAL";
VAL_ 833 LAST_RESET_CAUSE 0 "POWER_ON" 1 "BROWN_OUT" 2 "WATCHDOG" 3 "SOFTWARE" 4 "PIN";
VAL_ 1348 STATUS 0 "OK" 1 "BAD_INDEX" 2 "OUT_OF_RANGE" 3 "NOT_ALLOWED_WHILE_ARMED" 4 "FLASH_ERROR";
VAL_ 1349 STATUS 0 "OK" 1 "BAD_INDEX" 2 "OUT_OF_RANGE" 3 "NOT_ALLOWED_WHILE_ARMED" 4 "FLASH_ERROR";
VAL_ 1350 STATUS 0 "OK" 1 "BAD_INDEX" 2 "OUT_OF_RANGE" 3 "NOT_ALLOWED_WHILE_ARMED" 4 "FLASH_ERROR";
VAL_ 328 MODE 0 "COAST" 1 "BRAKE" 2 "VELOCITY" 3 "OPEN_LOOP_DUTY";
VAL_ 584 STATE 0 "BOOT" 1 "DISARMED" 2 "ARMED" 3 "FAULT" 4 "ESTOP" 5 "BOOTLOADER";
VAL_ 1608 STATE 0 "BOOT" 1 "DISARMED" 2 "ARMED" 3 "FAULT" 4 "ESTOP" 5 "BOOTLOADER";
VAL_ 1608 NODE_TYPE 1 "DRIVE" 2 "ARM" 3 "SCIENCE" 4 "FPGA" 5 "POWER";
VAL_ 847 SEVERITY 0 "INFO" 1 "WARNING" 2 "ERROR" 3 "CRITICAL";
VAL_ 841 LAST_RESET_CAUSE 0 "POWER_ON" 1 "BROWN_OUT" 2 "WATCHDOG" 3 "SOFTWARE" 4 "PIN";
VAL_ 1356 STATUS 0 "OK" 1 "BAD_INDEX" 2 "OUT_OF_RANGE" 3 "NOT_ALLOWED_WHILE_ARMED" 4 "FLASH_ERROR";
VAL_ 1357 STATUS 0 "OK" 1 "BAD_INDEX" 2 "OUT_OF_RANGE" 3 "NOT_ALLOWED_WHILE_ARMED" 4 "FLASH_ERROR";
VAL_ 1358 STATUS 0 "OK" 1 "BAD_INDEX" 2 "OUT_OF_RANGE" 3 "NOT_ALLOWED_WHILE_ARMED" 4 "FLASH_ERROR";
VAL_ 1696 STATE 0 "BOOT" 1 "DISARMED" 2 "ARMED" 3 "FAULT" 4 "ESTOP" 5 "BOOTLOADER";
VAL_ 1531 NODE_TYPE 1 "DRIVE" 2 "ARM" 3 "SCIENCE" 4 "FPGA" 5 "POWER";
VAL_ 1531 HW_TARGET 0 "ESP32" 1 "ESP32S3";
VAL_ 1696 NODE_TYPE 1 "DRIVE" 2 "ARM" 3 "SCIENCE" 4 "FPGA" 5 "POWER";
VAL_ 935 SEVERITY 0 "INFO" 1 "WARNING" 2 "ERROR" 3 "CRITICAL";
